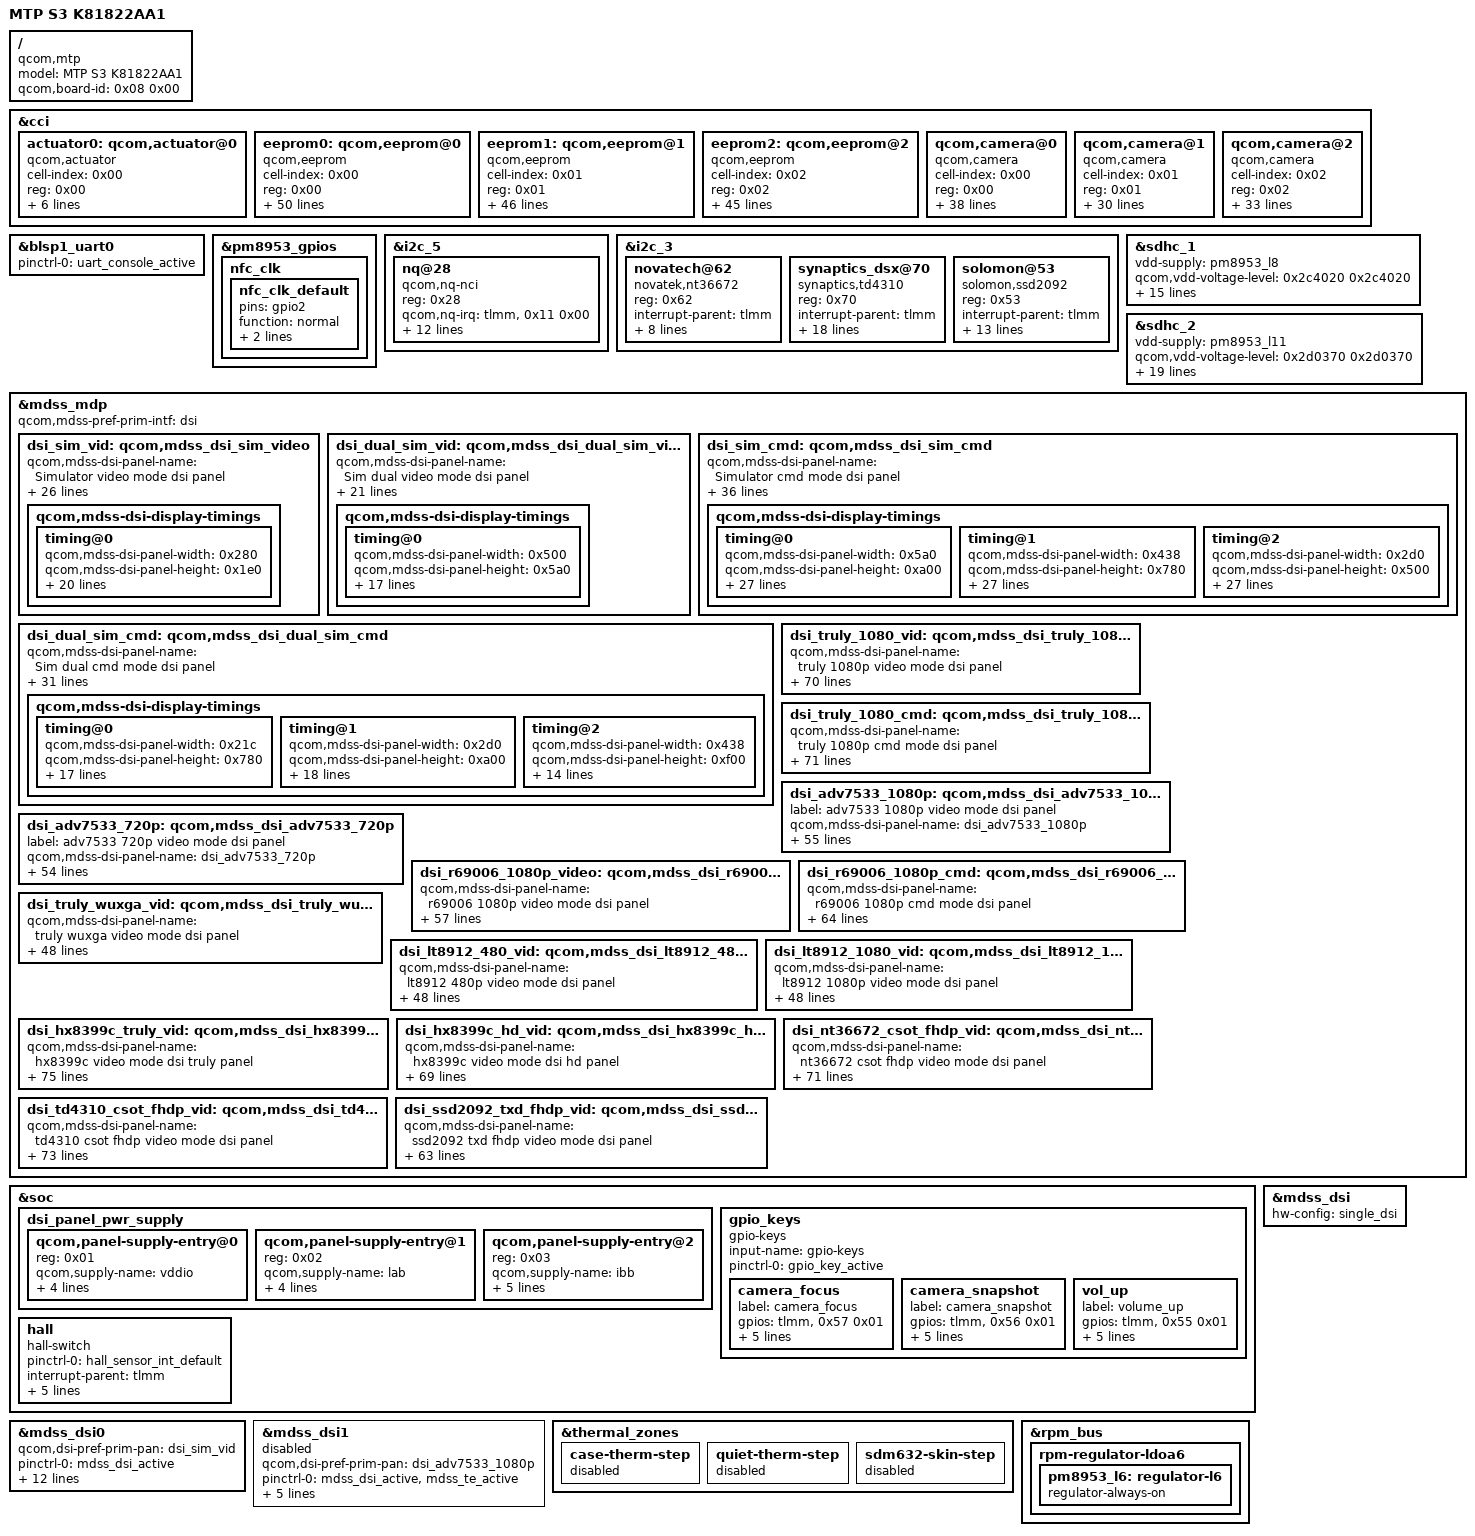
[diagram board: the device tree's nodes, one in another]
/dts-v1/;
/plugin/;

/ {
	model = "MTP S3 K81822AA1";
	compatible = "qcom,mtp";
	qcom,board-id = <0x08 0x00>;

	fragment@0 {
		target = <&cci>;

		__overlay__ {

			actuator0: qcom,actuator@0 {
				cell-index = <0x00>;
				reg = <0x00>;
				compatible = "qcom,actuator";
				qcom,cci-master = <0x00>;
				cam_vaf-supply = <&pm8953_l17>;
				qcom,cam-vreg-name = "cam_vaf";
				qcom,cam-vreg-min-voltage = <0x2b7cd0>;
				qcom,cam-vreg-max-voltage = <0x2b7cd0>;
				qcom,cam-vreg-op-mode = <0x13880>;
			};

			eeprom0: qcom,eeprom@0 {
				cell-index = <0x00>;
				reg = <0x00>;
				compatible = "qcom,eeprom";
				qcom,cci-master = <0x00>;
				qcom,eeprom-name = "gt24c64a_imx362";
				qcom,slave-addr = <0xa0>;
				qcom,num-blocks = <0x03>;
				qcom,page0 = <0x00 0x00 0x01 0x55 0x01 0x01>;
				qcom,pageen0 = <0x00 0x02 0x01 0xff 0x01 0x01>;
				qcom,poll0 = <0x00 0x00 0x02 0x00 0x01 0x01>;
				qcom,mem0 = <0x2b 0x00 0x02 0x00 0x01 0x00>;
				qcom,page1 = <0x00 0x00 0x01 0x55 0x01 0x01>;
				qcom,pageen1 = <0x00 0x02 0x01 0xff 0x01 0x01>;
				qcom,poll1 = <0x00 0x00 0x02 0x00 0x01 0x01>;
				qcom,mem1 = <0x132f 0x2b 0x02 0x00 0x01 0x00>;
				qcom,page2 = <0x00 0x00 0x01 0x55 0x01 0x01>;
				qcom,pageen2 = <0x00 0x02 0x01 0xff 0x01 0x01>;
				qcom,poll2 = <0x00 0x00 0x02 0x00 0x01 0x01>;
				qcom,mem2 = <0x2c 0x1a6c 0x02 0x00 0x01 0x00>;
				cam_vio-supply = <&pm8953_l6>;
				cam_vdig-supply = <&pm8953_l2>;
				cam_vana-supply = <&pm8953_l22>;
				qcom,cam-vreg-name = "cam_vio", "cam_vdig", "cam_vana";
				qcom,cam-vreg-min-voltage = <0x1b7740 0x100590 0x2ab980>;
				qcom,cam-vreg-max-voltage = <0x1b7740 0x100590 0x2ab980>;
				qcom,cam-vreg-op-mode = <0x13880 0x19a28 0x13880>;
				pinctrl-names = "cam_default", "cam_suspend";
				pinctrl-0 = <&cam_sensor_mclk0_default>, <&cam_sensor_rear_default>, <&cam_sensor_rear_vana>;
				pinctrl-1 = <&cam_sensor_mclk0_sleep>, <&cam_sensor_rear_sleep>, <&cam_sensor_rear_vana_sleep>;
				gpios = <&tlmm>, <0x1a 0x00>, <&tlmm>, <0x28 0x00>, <&tlmm>, <0x86 0x00>;
				qcom,gpio-reset = <0x01>;
				qcom,gpio-vana = <0x02>;
				qcom,gpio-req-tbl-num = <0x00 0x01 0x02>;
				qcom,gpio-req-tbl-flags = <0x01 0x00 0x00>;
				qcom,gpio-req-tbl-label = "CAMIF_MCLK0", "CAM_RESET0", "CAM_VANA";
				qcom,cam-power-seq-type = "sensor_gpio", "sensor_gpio", "sensor_vreg", "sensor_vreg";
				qcom,cam-power-seq-val = "sensor_gpio_vana", "sensor_gpio_vana", "cam_vdig", "cam_vio";
				qcom,cam-power-seq-cfg-val = <0x00 0x01 0x01 0x01>;
				qcom,cam-power-seq-delay = <0x01 0x01 0x01 0x01>;
				status = "ok";
				clocks = <&clock_gcc>, <0x266b3853>, <&clock_gcc>, <0x80902deb>;
				clock-names = "cam_src_clk", "cam_clk";
				qcom,clock-rates = <0x16e3600 0x00>;
			};

			eeprom1: qcom,eeprom@1 {
				cell-index = <0x01>;
				reg = <0x01>;
				compatible = "qcom,eeprom";
				qcom,cci-master = <0x00>;
				qcom,eeprom-name = "s5k5e9";
				qcom,slave-addr = <0xa0>;
				qcom,num-blocks = <0x02>;
				qcom,page0 = <0x00 0x00 0x01 0x55 0x01 0x01>;
				qcom,pageen0 = <0x00 0x02 0x01 0xff 0x01 0x01>;
				qcom,poll0 = <0x00 0x00 0x02 0x00 0x01 0x01>;
				qcom,mem0 = <0x2b 0x00 0x02 0x00 0x01 0x00>;
				qcom,page1 = <0x00 0x00 0x01 0x55 0x01 0x01>;
				qcom,pageen1 = <0x00 0x02 0x01 0xff 0x01 0x01>;
				qcom,poll1 = <0x00 0x00 0x02 0x00 0x01 0x01>;
				qcom,mem1 = <0x712 0x135a 0x02 0x00 0x01 0x00>;
				cam_vio-supply = <&pm8953_l6>;
				cam_vdig-supply = <&pm8953_l2>;
				cam_vana-supply = <&pm8953_l22>;
				qcom,cam-vreg-name = "cam_vio", "cam_vdig", "cam_vana";
				qcom,cam-vreg-min-voltage = <0x1b7740 0x100590 0x2ab980>;
				qcom,cam-vreg-max-voltage = <0x1b7740 0x100590 0x2ab980>;
				qcom,cam-vreg-op-mode = <0x13880 0x19a28 0x13880>;
				pinctrl-names = "cam_default", "cam_suspend";
				pinctrl-0 = <&cam_sensor_mclk0_default>, <&cam_sensor_rear_default>, <&cam_sensor_rear_vana>;
				pinctrl-1 = <&cam_sensor_mclk0_sleep>, <&cam_sensor_rear_sleep>, <&cam_sensor_rear_vana_sleep>;
				gpios = <&tlmm>, <0x1a 0x00>, <&tlmm>, <0x28 0x00>, <&tlmm>, <0x86 0x00>;
				qcom,gpio-reset = <0x01>;
				qcom,gpio-vana = <0x02>;
				qcom,gpio-req-tbl-num = <0x00 0x01 0x02>;
				qcom,gpio-req-tbl-flags = <0x01 0x00 0x00>;
				qcom,gpio-req-tbl-label = "CAMIF_MCLK0", "CAM_RESET0", "CAM_VANA";
				qcom,cam-power-seq-type = "sensor_gpio", "sensor_gpio", "sensor_vreg", "sensor_vreg";
				qcom,cam-power-seq-val = "sensor_gpio_vana", "sensor_gpio_vana", "cam_vdig", "cam_vio";
				qcom,cam-power-seq-cfg-val = <0x00 0x01 0x01 0x01>;
				qcom,cam-power-seq-delay = <0x01 0x01 0x01 0x01>;
				status = "ok";
				clocks = <&clock_gcc>, <0x266b3853>, <&clock_gcc>, <0x80902deb>;
				clock-names = "cam_src_clk", "cam_clk";
				qcom,clock-rates = <0x16e3600 0x00>;
			};

			eeprom2: qcom,eeprom@2 {
				cell-index = <0x02>;
				reg = <0x02>;
				qcom,eeprom-name = "s5k4h7";
				compatible = "qcom,eeprom";
				qcom,slave-addr = <0x5a>;
				qcom,cci-master = <0x01>;
				qcom,num-blocks = <0x01>;
				qcom,page0 = <0x00 0x100 0x02 0x01 0x01 0x01>;
				qcom,poll0 = <0x00 0x00 0x02 0x00 0x01 0x00>;
				qcom,mem0 = <0x7c0 0x00 0x02 0x00 0x01 0x00>;
				cam_vdig-supply = <&pm8953_l23>;
				cam_vio-supply = <&pm8953_l6>;
				cam_vana-supply = <&pm8953_l22>;
				qcom,cam-vreg-name = "cam_vdig", "cam_vio", "cam_vana";
				qcom,cam-vreg-min-voltage = <0x124f80 0x1b7740 0x2ab980>;
				qcom,cam-vreg-max-voltage = <0x124f80 0x1b7740 0x2ab980>;
				qcom,cam-vreg-op-mode = <0x19a28 0x13880 0x13880>;
				qcom,gpio-no-mux = <0x00>;
				pinctrl-names = "cam_default", "cam_suspend";
				pinctrl-0 = <&cam_sensor_mclk1_default>, <&cam_sensor_front1_default>;
				pinctrl-1 = <&cam_sensor_mclk1_sleep>, <&cam_sensor_front1_sleep>;
				gpios = <&tlmm>, <0x1b 0x00>, <&tlmm>, <0x81 0x00>, <&tlmm>, <0x82 0x00>;
				qcom,gpio-reset = <0x01>;
				qcom,gpio-standby = <0x02>;
				qcom,gpio-req-tbl-num = <0x00 0x01 0x02>;
				qcom,gpio-req-tbl-flags = <0x01 0x00 0x00>;
				qcom,gpio-req-tbl-label = "CAMIF_MCLK2", "CAM_RESET2", "CAM_STANDBY2";
				qcom,cam-power-seq-type = "sensor_gpio", "sensor_gpio", "sensor_vreg", "sensor_vreg", "sensor_vreg", "sensor_gpio", "sensor_gpio", "sensor_clk";
				qcom,cam-power-seq-val = "sensor_gpio_reset", "sensor_gpio_standby", "cam_vana", "cam_vio", "cam_vdig", "sensor_gpio_reset", "sensor_gpio_standby", "sensor_cam_mclk";
				qcom,cam-power-seq-cfg-val = <0x00 0x00 0x01 0x01 0x01 0x01 0x01 0x16e3600>;
				qcom,cam-power-seq-delay = <0x01 0x01 0x00 0x00 0x00 0x01 0x05 0x05>;
				status = "ok";
				clocks = <&clock_gcc>, <0xa73cad0c>, <&clock_gcc>, <0x5002d85f>;
				clock-names = "cam_src_clk", "cam_clk";
				qcom,clock-rates = <0x16e3600 0x00>;
			};

			qcom,camera@0 {
				cell-index = <0x00>;
				compatible = "qcom,camera";
				reg = <0x00>;
				qcom,csiphy-sd-index = <0x00>;
				qcom,csid-sd-index = <0x00>;
				qcom,mount-angle = <0x5a>;
				qcom,led-flash-src = <&led_flash0>;
				qcom,eeprom-src = <&eeprom0>;
				qcom,actuator-src = <&actuator0>;
				cam_vio-supply = <&pm8953_l6>;
				cam_vdig-supply = <&pm8953_l2>;
				cam_vaf-supply = <&pm8953_l17>;
				cam_vana-supply = <&pm8953_l22>;
				qcom,cam-vreg-name = "cam_vio", "cam_vdig", "cam_vaf", "cam_vana";
				qcom,cam-vreg-min-voltage = <0x1b7740 0x100590 0x2b7cd0 0x2ab980>;
				qcom,cam-vreg-max-voltage = <0x1b7740 0x100590 0x2b7cd0 0x2ab980>;
				qcom,cam-vreg-op-mode = <0x13880 0x19a28 0x186a0 0x13880>;
				pinctrl-names = "cam_default", "cam_suspend";
				pinctrl-0 = <&cam_sensor_mclk0_default>, <&cam_sensor_rear_default>, <&cam_sensor_rear_vana>;
				pinctrl-1 = <&cam_sensor_mclk0_sleep>, <&cam_sensor_rear_sleep>, <&cam_sensor_rear_vana_sleep>;
				gpios = <&tlmm>, <0x1a 0x00>, <&tlmm>, <0x28 0x00>, <&tlmm>, <0x86 0x00>;
				qcom,gpio-reset = <0x01>;
				qcom,gpio-vana = <0x02>;
				qcom,gpio-req-tbl-num = <0x00 0x01 0x02>;
				qcom,gpio-req-tbl-flags = <0x01 0x00 0x00>;
				qcom,gpio-req-tbl-label = "CAMIF_MCLK0", "CAM_RESET0", "CAM_VANA";
				qcom,sensor-position = <0x00>;
				qcom,sensor-mode = <0x00>;
				qcom,cci-master = <0x00>;
				status = "ok";
				clocks = <&clock_gcc>, <0x266b3853>, <&clock_gcc>, <0x80902deb>;
				clock-names = "cam_src_clk", "cam_clk";
				qcom,clock-rates = <0x16e3600 0x00>;
			};

			qcom,camera@1 {
				cell-index = <0x01>;
				compatible = "qcom,camera";
				reg = <0x01>;
				qcom,csiphy-sd-index = <0x01>;
				qcom,csid-sd-index = <0x01>;
				qcom,mount-angle = <0x5a>;
				qcom,eeprom-src = <&eeprom1>;
				cam_vdig-supply = <&pm8953_l23>;
				cam_vana-supply = <&pm8953_l22>;
				cam_vio-supply = <&pm8953_l6>;
				qcom,cam-vreg-name = "cam_vdig", "cam_vio", "cam_vana";
				qcom,cam-vreg-min-voltage = <0x124f80 0x1b7740 0x2ab980>;
				qcom,cam-vreg-max-voltage = <0x124f80 0x1b7740 0x2ab980>;
				qcom,cam-vreg-op-mode = <0x30d40 0x13880 0x13880>;
				pinctrl-names = "cam_default", "cam_suspend";
				pinctrl-0 = <&cam_sensor_mclk2_default>, <&cam_sensor_front_default>;
				pinctrl-1 = <&cam_sensor_mclk2_sleep>, <&cam_sensor_front_sleep>;
				gpios = <&tlmm>, <0x1c 0x00>, <&tlmm>, <0x83 0x00>;
				qcom,gpio-reset = <0x01>;
				qcom,gpio-req-tbl-num = <0x00 0x01>;
				qcom,gpio-req-tbl-flags = <0x01 0x00>;
				qcom,gpio-req-tbl-label = "CAMIF_MCLK1", "CAM_RESET1";
				qcom,sensor-position = <0x100>;
				qcom,sensor-mode = <0x01>;
				qcom,cci-master = <0x01>;
				status = "ok";
				clocks = <&clock_gcc>, <0x42545468>, <&clock_gcc>, <0x222f8fff>;
				clock-names = "cam_src_clk", "cam_clk";
				qcom,clock-rates = <0x16e3600 0x00>;
			};

			qcom,camera@2 {
				cell-index = <0x02>;
				compatible = "qcom,camera";
				reg = <0x02>;
				qcom,csiphy-sd-index = <0x02>;
				qcom,csid-sd-index = <0x02>;
				qcom,mount-angle = <0x10e>;
				qcom,eeprom-src = <&eeprom2>;
				cam_vdig-supply = <&pm8953_l23>;
				cam_vio-supply = <&pm8953_l6>;
				cam_vana-supply = <&pm8953_l22>;
				qcom,cam-vreg-name = "cam_vdig", "cam_vio", "cam_vana";
				qcom,cam-vreg-min-voltage = <0x124f80 0x1b7740 0x2ab980>;
				qcom,cam-vreg-max-voltage = <0x124f80 0x1b7740 0x2ab980>;
				qcom,cam-vreg-op-mode = <0x19a28 0x13880 0x13880>;
				qcom,gpio-no-mux = <0x00>;
				pinctrl-names = "cam_default", "cam_suspend";
				pinctrl-0 = <&cam_sensor_mclk1_default>, <&cam_sensor_front1_default>;
				pinctrl-1 = <&cam_sensor_mclk1_sleep>, <&cam_sensor_front1_sleep>;
				gpios = <&tlmm>, <0x1b 0x00>, <&tlmm>, <0x81 0x00>, <&tlmm>, <0x82 0x00>;
				qcom,gpio-reset = <0x01>;
				qcom,gpio-standby = <0x02>;
				qcom,gpio-req-tbl-num = <0x00 0x01 0x02>;
				qcom,gpio-req-tbl-flags = <0x01 0x00 0x00>;
				qcom,gpio-req-tbl-label = "CAMIF_MCLK2", "CAM_RESET2", "CAM_STANDBY2";
				qcom,sensor-position = <0x01>;
				qcom,sensor-mode = <0x00>;
				qcom,cci-master = <0x01>;
				status = "ok";
				clocks = <&clock_gcc>, <0xa73cad0c>, <&clock_gcc>, <0x5002d85f>;
				clock-names = "cam_src_clk", "cam_clk";
				qcom,clock-rates = <0x16e3600 0x00>;
			};
		};
	};

	fragment@1 {
		target = <&blsp1_uart0>;

		__overlay__ {
			status = "ok";
			pinctrl-names = "default";
			pinctrl-0 = <&uart_console_active>;
		};
	};

	fragment@2 {
		target = <&pm8953_gpios>;

		__overlay__ {

			nfc_clk {

				nfc_clk_default: nfc_clk_default {
					pins = "gpio2";
					function = "normal";
					input-enable;
					power-source = <0x01>;
				};
			};
		};
	};

	fragment@3 {
		target = <&i2c_5>;

		__overlay__ {
			status = "ok";

			nq@28 {
				compatible = "qcom,nq-nci";
				reg = <0x28>;
				qcom,nq-irq = <&tlmm>, <0x11 0x00>;
				qcom,nq-ven = <&tlmm>, <0x10 0x00>;
				qcom,nq-firm = <&tlmm>, <0x3e 0x00>;
				qcom,nq-clkreq = <&pm8953_gpios>, <0x02 0x00>;
				qcom,nq-esepwr = <&tlmm>, <0x8d 0x00>;
				interrupt-parent = <&tlmm>;
				qcom,clk-src = "BBCLK2";
				interrupts = <0x11 0x00>;
				interrupt-names = "nfc_irq";
				pinctrl-names = "nfc_active", "nfc_suspend";
				pinctrl-0 = <&nfc_int_active>, <&nfc_disable_active>, <&nfc_clk_default>;
				pinctrl-1 = <&nfc_int_suspend>, <&nfc_disable_suspend>;
				clocks = <&clock_gcc>, <0x498938e5>;
				clock-names = "ref_clk";
			};
		};
	};

	fragment@4 {
		target = <&i2c_3>;

		__overlay__ {
			status = "okay";

			novatech@62 {
				compatible = "novatek,nt36672", "novatek,NVT-ts";
				reg = <0x62>;
				interrupt-parent = <&tlmm>;
				status = "ok";
				novatek,reset-gpio = <&tlmm>, <0x40 0x00>;
				novatek,irq-gpio = <&tlmm>, <0x41 0x2001>;
				vdd-supply = <&pm8953_l5>;
				lab-supply = <&lcdb_ldo_vreg>;
				ibb-supply = <&lcdb_ncp_vreg>;
				touchpanel,rst-gpio = <&tlmm>, <0x40 0x00>;
				touchpanel,irq-gpio = <&tlmm>, <0x41 0x00>;
				touchpanel,open_short_not_use_fw;
			};

			synaptics_dsx@70 {
				compatible = "synaptics,td4310", "synaptics,dsx-i2c";
				reg = <0x70>;
				interrupt-parent = <&tlmm>;
				interrupts = <0x41 0x2008>;
				pinctrl-names = "default";
				pinctrl-0 = <&ts_int_active>;
				vdd-supply = <&pm8953_l5>;
				lab-supply = <&lcdb_ldo_vreg>;
				ibb-supply = <&lcdb_ncp_vreg>;
				synaptics,bus-reg-name = "vdd";
				synaptics,lab-reg-name = "lab";
				synaptics,ibb-reg-name = "ibb";
				synaptics,ub-i2c-addr = <0x2c>;
				synaptics,irq-gpio = <&tlmm>, <0x41 0x2008>;
				synaptics,rst-gpio = <&tlmm>, <0x3d 0x00>;
				synaptics,irq-on-state = <0x00>;
				synaptics,power-delay-ms = <0x00>;
				synaptics,reset-delay-ms = <0xc8>;
				synaptics,reset-on-state = <0x00>;
				synaptics,reset-active-ms = <0x14>;
				touchpanel,rst-gpio = <&tlmm>, <0x3d 0x00>;
				touchpanel,irq-gpio = <&tlmm>, <0x41 0x00>;
			};

			solomon@53 {
				compatible = "solomon,ssd2092";
				reg = <0x53>;
				interrupt-parent = <&tlmm>;
				interrupts = <0x41 0x2008>;
				vcc-i2c-supply = <&pm8953_l5>;
				lab-supply = <&lcdb_ldo_vreg>;
				ibb-supply = <&lcdb_ncp_vreg>;
				solomon,bus-reg-name = "vcc-i2c";
				solomon,lab-reg-name = "lab";
				solomon,ibb-reg-name = "ibb";
				interrupt-gpios = <&tlmm>, <0x41 0x00>;
				reset-gpios = <&tlmm>, <0x40 0x00>;
				lcd-reset-gpios = <&tlmm>, <0x3d 0x00>;
				touchpanel,rst-gpio = <&tlmm>, <0x3d 0x00>;
				touchpanel,irq-gpio = <&tlmm>, <0x41 0x00>;
				touchpanel,open_short_not_use_fw;
			};
		};
	};

	fragment@5 {
		target = <&sdhc_1>;

		__overlay__ {
			vdd-supply = <&pm8953_l8>;
			qcom,vdd-voltage-level = <0x2c4020 0x2c4020>;
			qcom,vdd-current-level = <0xc8 0x8b290>;
			vdd-io-supply = <&pm8953_l5>;
			qcom,vdd-io-always-on;
			qcom,vdd-io-lpm-sup;
			qcom,vdd-io-voltage-level = <0x1b7740 0x1b7740>;
			qcom,vdd-io-current-level = <0xc8 0x4f588>;
			pinctrl-names = "active", "sleep";
			pinctrl-0 = <&sdc1_clk_on>, <&sdc1_cmd_on>, <&sdc1_data_on>, <&sdc1_rclk_on>;
			pinctrl-1 = <&sdc1_clk_off>, <&sdc1_cmd_off>, <&sdc1_data_off>, <&sdc1_rclk_off>;
			qcom,clk-rates = <0x61a80 0x1312d00 0x17d7840 0x2faf080 0x5f5e100 0xb71b000 0x16e36000>;
			qcom,nonremovable;
			qcom,bus-speed-mode = "HS400_1p8v", "HS200_1p8v", "DDR_1p8v";
			status = "ok";
		};
	};

	fragment@6 {
		target = <&sdhc_2>;

		__overlay__ {
			vdd-supply = <&pm8953_l11>;
			qcom,vdd-voltage-level = <0x2d0370 0x2d0370>;
			qcom,vdd-current-level = <0x3a98 0xc3500>;
			vdd-io-supply = <&pm8953_l12>;
			qcom,vdd-io-voltage-level = <0x1b7740 0x2d0370>;
			qcom,vdd-io-current-level = <0xc8 0x55f0>;
			pinctrl-names = "active", "sleep";
			pinctrl-0 = <&sdc2_clk_on>, <&sdc2_cmd_on>, <&sdc2_data_on>, <&sdc2_cd_on>;
			pinctrl-1 = <&sdc2_clk_off>, <&sdc2_cmd_off>, <&sdc2_data_off>;
			#address-cells = <0x00>;
			interrupt-parent = <&sdhc_2>;
			interrupts = <0x00 0x01 0x02>;
			#interrupt-cells = <0x01>;
			interrupt-map-mask = <0xffffffff>;
			interrupt-map = <0x00>, <&intc>, <0x00 0x7d 0x00 0x01>, <&intc>, <0x00 0xdd 0x00 0x02>, <&tlmm>, <0x85 0x00>;
			interrupt-names = "hc_irq", "pwr_irq", "status_irq";
			cd-gpios = <&tlmm>, <0x85 0x00>;
			qcom,clk-rates = <0x61a80 0x1312d00 0x17d7840 0x2faf080 0x5f5e100 0xbebc200>;
			qcom,bus-speed-mode = "SDR12", "SDR25", "SDR50", "DDR50", "SDR104";
			status = "ok";
		};
	};

	fragment@7 {
		target = <&mdss_mdp>;

		__overlay__ {

			dsi_sim_vid: qcom,mdss_dsi_sim_video {
				qcom,mdss-dsi-panel-name = "Simulator video mode dsi panel";
				qcom,mdss-dsi-panel-type = "dsi_video_mode";
				qcom,mdss-dsi-virtual-channel-id = <0x00>;
				qcom,mdss-dsi-stream = <0x00>;
				qcom,mdss-dsi-bpp = <0x18>;
				qcom,mdss-dsi-underflow-color = <0xff>;
				qcom,mdss-dsi-border-color = <0x00>;
				qcom,mdss-dsi-panel-hdr-enabled;
				qcom,mdss-dsi-panel-hdr-color-primaries = <0x38a4 0x3c8c 0x7d00 0x4268 0x3c8c 0x7530 0x1f40 0xbb8>;
				qcom,mdss-dsi-panel-peak-brightness = <0x401640>;
				qcom,mdss-dsi-panel-blackness-level = <0xc9e>;
				qcom,mdss-dsi-traffic-mode = "non_burst_sync_event";
				qcom,mdss-dsi-bllp-eof-power-mode;
				qcom,mdss-dsi-bllp-power-mode;
				qcom,mdss-dsi-lane-0-state;
				qcom,mdss-dsi-lane-1-state;
				qcom,mdss-dsi-lane-2-state;
				qcom,mdss-dsi-lane-3-state;
				qcom,mdss-dsi-t-clk-post = <0x04>;
				qcom,mdss-dsi-t-clk-pre = <0x1b>;
				qcom,mdss-dsi-dma-trigger = "trigger_sw";
				qcom,mdss-dsi-mdp-trigger = "none";
				qcom,mdss-dsi-reset-sequence = <0x01 0x00 0x00 0x00 0x01 0x00>;
				qcom,panel-ack-disabled;

				qcom,mdss-dsi-display-timings {

					timing@0 {
						qcom,mdss-dsi-panel-width = <0x280>;
						qcom,mdss-dsi-panel-height = <0x1e0>;
						qcom,mdss-dsi-h-front-porch = <0x08>;
						qcom,mdss-dsi-h-back-porch = <0x08>;
						qcom,mdss-dsi-h-pulse-width = <0x08>;
						qcom,mdss-dsi-h-sync-skew = <0x00>;
						qcom,mdss-dsi-v-back-porch = <0x06>;
						qcom,mdss-dsi-v-front-porch = <0x06>;
						qcom,mdss-dsi-v-pulse-width = <0x02>;
						qcom,mdss-dsi-h-left-border = <0x00>;
						qcom,mdss-dsi-h-right-border = <0x00>;
						qcom,mdss-dsi-v-top-border = <0x00>;
						qcom,mdss-dsi-v-bottom-border = <0x00>;
						qcom,mdss-dsi-panel-framerate = <0x3c>;
						qcom,mdss-dsi-panel-timings = <0x00 0x00 0x00>;
						qcom,mdss-dsi-on-command = [32 01 00 00 00 00 02 00 00];
						qcom,mdss-dsi-off-command = [22 01 00 00 00 00 02 00 00];
						qcom,mdss-dsi-on-command-state = "dsi_lp_mode";
						qcom,mdss-dsi-off-command-state = "dsi_lp_mode";
						qcom,mdss-dsi-h-sync-pulse = <0x00>;
					};
				};
			};
		};
	};

	fragment@8 {
		target = <&mdss_mdp>;

		__overlay__ {

			dsi_dual_sim_vid: qcom,mdss_dsi_dual_sim_video {
				qcom,mdss-dsi-panel-name = "Sim dual video mode dsi panel";
				qcom,mdss-dsi-panel-type = "dsi_video_mode";
				qcom,mdss-dsi-virtual-channel-id = <0x00>;
				qcom,mdss-dsi-stream = <0x00>;
				qcom,mdss-dsi-bpp = <0x18>;
				qcom,mdss-dsi-underflow-color = <0xff>;
				qcom,mdss-dsi-border-color = <0x00>;
				qcom,mdss-dsi-traffic-mode = "non_burst_sync_event";
				qcom,mdss-dsi-bllp-eof-power-mode;
				qcom,mdss-dsi-bllp-power-mode;
				qcom,mdss-dsi-panel-broadcast-mode;
				qcom,mdss-dsi-lane-0-state;
				qcom,mdss-dsi-lane-1-state;
				qcom,mdss-dsi-lane-2-state;
				qcom,mdss-dsi-lane-3-state;
				qcom,mdss-dsi-bl-max-level = <0xfff>;
				qcom,mdss-dsi-dma-trigger = "trigger_sw";
				qcom,mdss-dsi-mdp-trigger = "none";
				qcom,mdss-dsi-reset-sequence = <0x01 0x14 0x00 0xc8 0x01 0x14>;
				qcom,panel-ack-disabled;

				qcom,mdss-dsi-display-timings {

					timing@0 {
						qcom,mdss-dsi-panel-width = <0x500>;
						qcom,mdss-dsi-panel-height = <0x5a0>;
						qcom,mdss-dsi-h-front-porch = <0x78>;
						qcom,mdss-dsi-h-back-porch = <0x2c>;
						qcom,mdss-dsi-h-pulse-width = <0x10>;
						qcom,mdss-dsi-h-sync-skew = <0x00>;
						qcom,mdss-dsi-v-back-porch = <0x04>;
						qcom,mdss-dsi-v-front-porch = <0x08>;
						qcom,mdss-dsi-v-pulse-width = <0x04>;
						qcom,mdss-dsi-h-left-border = <0x00>;
						qcom,mdss-dsi-h-right-border = <0x00>;
						qcom,mdss-dsi-v-top-border = <0x00>;
						qcom,mdss-dsi-v-bottom-border = <0x00>;
						qcom,mdss-dsi-h-sync-pulse = <0x00>;
						qcom,mdss-dsi-panel-framerate = <0x3c>;
						qcom,mdss-dsi-on-command-state = "dsi_lp_mode";
						qcom,mdss-dsi-off-command = [05 01 00 00 32 00 02 28 00 05 01 00 00 78 00 02 10 00];
						qcom,mdss-dsi-off-command-state = "dsi_hs_mode";
					};
				};
			};
		};
	};

	fragment@9 {
		target = <&mdss_mdp>;

		__overlay__ {

			dsi_sim_cmd: qcom,mdss_dsi_sim_cmd {
				qcom,mdss-dsi-panel-name = "Simulator cmd mode dsi panel";
				qcom,mdss-dsi-panel-type = "dsi_cmd_mode";
				qcom,mdss-dsi-virtual-channel-id = <0x00>;
				qcom,mdss-dsi-stream = <0x00>;
				qcom,mdss-dsi-bpp = <0x18>;
				qcom,mdss-dsi-color-order = "rgb_swap_rgb";
				qcom,mdss-dsi-underflow-color = <0xff>;
				qcom,mdss-dsi-border-color = <0x00>;
				qcom,mdss-dsi-traffic-mode = "non_burst_sync_event";
				qcom,mdss-dsi-bllp-eof-power-mode;
				qcom,mdss-dsi-bllp-power-mode;
				qcom,mdss-dsi-lane-0-state;
				qcom,mdss-dsi-lane-1-state;
				qcom,mdss-dsi-lane-2-state;
				qcom,mdss-dsi-lane-3-state;
				qcom,mdss-dsi-reset-sequence = <0x01 0x0a 0x00 0x0a 0x01 0x0a>;
				qcom,mdss-dsi-t-clk-post = <0x03>;
				qcom,mdss-dsi-t-clk-pre = <0x27>;
				qcom,mdss-dsi-bl-max-level = <0xfff>;
				qcom,mdss-dsi-dma-trigger = "trigger_sw";
				qcom,mdss-dsi-mdp-trigger = "none";
				qcom,mdss-dsi-te-pin-select = <0x01>;
				qcom,mdss-dsi-wr-mem-start = <0x2c>;
				qcom,mdss-dsi-wr-mem-continue = <0x3c>;
				qcom,mdss-dsi-te-dcs-command = <0x01>;
				qcom,mdss-dsi-te-check-enable;
				qcom,mdss-dsi-te-using-wd;
				qcom,mdss-dsi-te-using-te-pin;
				qcom,mdss-dsi-panel-hdr-enabled;
				qcom,ulps-enabled;
				qcom,mdss-dsi-panel-hdr-color-primaries = <0x38a4 0x3c8c 0x7d00 0x4268 0x3c8c 0x7530 0x1f40 0xbb8>;
				qcom,mdss-dsi-panel-peak-brightness = <0x401640>;
				qcom,mdss-dsi-panel-blackness-level = <0xc9e>;
				qcom,panel-ack-disabled;

				qcom,mdss-dsi-display-timings {

					timing@0 {
						qcom,mdss-dsi-panel-width = <0x5a0>;
						qcom,mdss-dsi-panel-height = <0xa00>;
						qcom,mdss-dsi-h-front-porch = <0x78>;
						qcom,mdss-dsi-h-back-porch = <0x64>;
						qcom,mdss-dsi-h-pulse-width = <0x28>;
						qcom,mdss-dsi-h-sync-skew = <0x00>;
						qcom,mdss-dsi-v-back-porch = <0x64>;
						qcom,mdss-dsi-v-front-porch = <0x64>;
						qcom,mdss-dsi-v-pulse-width = <0x28>;
						qcom,mdss-dsi-h-left-border = <0x00>;
						qcom,mdss-dsi-h-right-border = <0x00>;
						qcom,mdss-dsi-v-top-border = <0x00>;
						qcom,mdss-dsi-v-bottom-border = <0x00>;
						qcom,mdss-dsi-panel-framerate = <0x3c>;
						qcom,mdss-dsi-panel-timings = <0x210909 0x24230808 0x8030400>;
						qcom,mdss-dsi-on-command = <0x29010000 0x2b0 0x3050100 0xa0001 0x150100 0xa0002 0x3a773901 0xa00 0x52a0000 0x4ff3901 0xa00 0x52b0000 0x59f1501 0xa00 0x2350039 0x100000a 0x34400 0x150100 0xa0002 0x51ff1501 0xa00 0x2532415 0x100000a 0x25500 0x5010000 0x78000111 0x5010000 0x10000129>;
						qcom,mdss-dsi-on-command-state = "dsi_lp_mode";
						qcom,mdss-dsi-off-command = [05 01 00 00 32 00 02 28 00 05 01 00 00 78 00 02 10 00];
						qcom,mdss-dsi-off-command-state = "dsi_hs_mode";
						qcom,compression-mode = "dsc";
						qcom,mdss-dsc-slice-height = <0x28>;
						qcom,mdss-dsc-slice-width = <0x2d0>;
						qcom,mdss-dsc-slice-per-pkt = <0x01>;
						qcom,mdss-dsc-bit-per-component = <0x08>;
						qcom,mdss-dsc-bit-per-pixel = <0x08>;
						qcom,mdss-dsc-block-prediction-enable;
					};

					timing@1 {
						qcom,mdss-dsi-panel-width = <0x438>;
						qcom,mdss-dsi-panel-height = <0x780>;
						qcom,mdss-dsi-h-front-porch = <0x78>;
						qcom,mdss-dsi-h-back-porch = <0x1cc>;
						qcom,mdss-dsi-h-pulse-width = <0x28>;
						qcom,mdss-dsi-h-sync-skew = <0x00>;
						qcom,mdss-dsi-v-back-porch = <0x64>;
						qcom,mdss-dsi-v-front-porch = <0x2e4>;
						qcom,mdss-dsi-v-pulse-width = <0x28>;
						qcom,mdss-dsi-h-left-border = <0x00>;
						qcom,mdss-dsi-h-right-border = <0x00>;
						qcom,mdss-dsi-v-top-border = <0x00>;
						qcom,mdss-dsi-v-bottom-border = <0x00>;
						qcom,mdss-dsi-panel-framerate = <0x3c>;
						qcom,mdss-dsi-panel-timings = <0x210909 0x24230808 0x8030400>;
						qcom,mdss-dsi-on-command = <0x29010000 0x2b0 0x3050100 0xa0001 0x150100 0xa0002 0x3a773901 0xa00 0x52a0000 0x4ff3901 0xa00 0x52b0000 0x59f1501 0xa00 0x2350039 0x100000a 0x34400 0x150100 0xa0002 0x51ff1501 0xa00 0x2532415 0x100000a 0x25500 0x5010000 0x78000111 0x5010000 0x10000129>;
						qcom,mdss-dsi-on-command-state = "dsi_lp_mode";
						qcom,mdss-dsi-off-command = [05 01 00 00 32 00 02 28 00 05 01 00 00 78 00 02 10 00];
						qcom,mdss-dsi-off-command-state = "dsi_hs_mode";
						qcom,compression-mode = "dsc";
						qcom,mdss-dsc-slice-height = <0x28>;
						qcom,mdss-dsc-slice-width = <0x21c>;
						qcom,mdss-dsc-slice-per-pkt = <0x01>;
						qcom,mdss-dsc-bit-per-component = <0x08>;
						qcom,mdss-dsc-bit-per-pixel = <0x08>;
						qcom,mdss-dsc-block-prediction-enable;
					};

					timing@2 {
						qcom,mdss-dsi-panel-width = <0x2d0>;
						qcom,mdss-dsi-panel-height = <0x500>;
						qcom,mdss-dsi-h-front-porch = <0x64>;
						qcom,mdss-dsi-h-back-porch = <0x348>;
						qcom,mdss-dsi-h-pulse-width = <0x28>;
						qcom,mdss-dsi-h-sync-skew = <0x00>;
						qcom,mdss-dsi-v-back-porch = <0x64>;
						qcom,mdss-dsi-v-front-porch = <0x564>;
						qcom,mdss-dsi-v-pulse-width = <0x28>;
						qcom,mdss-dsi-h-left-border = <0x00>;
						qcom,mdss-dsi-h-right-border = <0x00>;
						qcom,mdss-dsi-v-top-border = <0x00>;
						qcom,mdss-dsi-v-bottom-border = <0x00>;
						qcom,mdss-dsi-panel-framerate = <0x3c>;
						qcom,mdss-dsi-panel-timings = <0x210909 0x24230808 0x8030400>;
						qcom,mdss-dsi-on-command = <0x29010000 0x2b0 0x3050100 0xa0001 0x150100 0xa0002 0x3a773901 0xa00 0x52a0000 0x4ff3901 0xa00 0x52b0000 0x59f1501 0xa00 0x2350039 0x100000a 0x34400 0x150100 0xa0002 0x51ff1501 0xa00 0x2532415 0x100000a 0x25500 0x5010000 0x78000111 0x5010000 0x10000129>;
						qcom,mdss-dsi-on-command-state = "dsi_lp_mode";
						qcom,mdss-dsi-off-command = [05 01 00 00 32 00 02 28 00 05 01 00 00 78 00 02 10 00];
						qcom,mdss-dsi-off-command-state = "dsi_hs_mode";
						qcom,compression-mode = "dsc";
						qcom,mdss-dsc-slice-height = <0x28>;
						qcom,mdss-dsc-slice-width = <0x168>;
						qcom,mdss-dsc-slice-per-pkt = <0x01>;
						qcom,mdss-dsc-bit-per-component = <0x08>;
						qcom,mdss-dsc-bit-per-pixel = <0x08>;
						qcom,mdss-dsc-block-prediction-enable;
					};
				};
			};
		};
	};

	fragment@10 {
		target = <&mdss_mdp>;

		__overlay__ {

			dsi_dual_sim_cmd: qcom,mdss_dsi_dual_sim_cmd {
				qcom,mdss-dsi-panel-name = "Sim dual cmd mode dsi panel";
				qcom,mdss-dsi-panel-type = "dsi_cmd_mode";
				qcom,mdss-dsi-virtual-channel-id = <0x00>;
				qcom,mdss-dsi-stream = <0x00>;
				qcom,mdss-dsi-bpp = <0x18>;
				qcom,mdss-dsi-color-order = "rgb_swap_rgb";
				qcom,mdss-dsi-underflow-color = <0xff>;
				qcom,mdss-dsi-border-color = <0x00>;
				qcom,mdss-dsi-traffic-mode = "non_burst_sync_event";
				qcom,mdss-dsi-bllp-eof-power-mode;
				qcom,mdss-dsi-bllp-power-mode;
				qcom,cmd-sync-wait-broadcast;
				qcom,mdss-dsi-lane-0-state;
				qcom,mdss-dsi-lane-1-state;
				qcom,mdss-dsi-lane-2-state;
				qcom,mdss-dsi-lane-3-state;
				qcom,mdss-dsi-hor-line-idle = <0x00 0x28 0x100 0x28 0x78 0x80 0x78 0xf0 0x40>;
				qcom,mdss-dsi-reset-sequence = <0x01 0x0a 0x00 0x0a 0x01 0x0a>;
				qcom,mdss-dsi-bl-max-level = <0xfff>;
				qcom,mdss-dsi-dma-trigger = "trigger_sw";
				qcom,mdss-dsi-mdp-trigger = "none";
				qcom,mdss-dsi-te-pin-select = <0x01>;
				qcom,mdss-dsi-wr-mem-start = <0x2c>;
				qcom,mdss-dsi-wr-mem-continue = <0x3c>;
				qcom,mdss-dsi-te-dcs-command = <0x01>;
				qcom,mdss-dsi-te-check-enable;
				qcom,mdss-dsi-te-using-wd;
				qcom,mdss-dsi-te-using-te-pin;
				qcom,panel-ack-disabled;

				qcom,mdss-dsi-display-timings {

					timing@0 {
						qcom,mdss-dsi-panel-width = <0x21c>;
						qcom,mdss-dsi-panel-height = <0x780>;
						qcom,mdss-dsi-h-front-porch = <0x1c>;
						qcom,mdss-dsi-h-back-porch = <0x04>;
						qcom,mdss-dsi-h-pulse-width = <0x04>;
						qcom,mdss-dsi-h-sync-skew = <0x00>;
						qcom,mdss-dsi-v-back-porch = <0x0c>;
						qcom,mdss-dsi-v-front-porch = <0x0c>;
						qcom,mdss-dsi-v-pulse-width = <0x02>;
						qcom,mdss-dsi-h-left-border = <0x00>;
						qcom,mdss-dsi-h-right-border = <0x00>;
						qcom,mdss-dsi-v-top-border = <0x00>;
						qcom,mdss-dsi-v-bottom-border = <0x00>;
						qcom,mdss-dsi-panel-framerate = <0x78>;
						qcom,mdss-dsi-on-command = <0x5010000 0x129>;
						qcom,mdss-dsi-on-command-state = "dsi_lp_mode";
						qcom,mdss-dsi-off-command = [05 01 00 00 00 00 02 28 00 05 01 00 00 00 00 02 10 00];
						qcom,mdss-dsi-off-command-state = "dsi_hs_mode";
					};

					timing@1 {
						qcom,mdss-dsi-panel-width = <0x2d0>;
						qcom,mdss-dsi-panel-height = <0xa00>;
						qcom,mdss-dsi-h-front-porch = <0x64>;
						qcom,mdss-dsi-h-back-porch = <0x20>;
						qcom,mdss-dsi-h-pulse-width = <0x10>;
						qcom,mdss-dsi-h-sync-skew = <0x00>;
						qcom,mdss-dsi-v-back-porch = <0x07>;
						qcom,mdss-dsi-v-front-porch = <0x08>;
						qcom,mdss-dsi-v-pulse-width = <0x01>;
						qcom,mdss-dsi-h-sync-pulse = <0x00>;
						qcom,mdss-dsi-h-left-border = <0x00>;
						qcom,mdss-dsi-h-right-border = <0x00>;
						qcom,mdss-dsi-v-top-border = <0x00>;
						qcom,mdss-dsi-v-bottom-border = <0x00>;
						qcom,mdss-dsi-panel-framerate = <0x3c>;
						qcom,mdss-dsi-on-command = <0x5010000 0x129>;
						qcom,mdss-dsi-on-command-state = "dsi_lp_mode";
						qcom,mdss-dsi-off-command = [05 01 00 00 00 00 02 28 00 05 01 00 00 00 00 02 10 00];
						qcom,mdss-dsi-off-command-state = "dsi_hs_mode";
					};

					timing@2 {
						qcom,mdss-dsi-panel-width = <0x438>;
						qcom,mdss-dsi-panel-height = <0xf00>;
						qcom,mdss-dsi-h-front-porch = <0x1e>;
						qcom,mdss-dsi-h-back-porch = <0x64>;
						qcom,mdss-dsi-h-pulse-width = <0x04>;
						qcom,mdss-dsi-h-sync-skew = <0x00>;
						qcom,mdss-dsi-v-back-porch = <0x07>;
						qcom,mdss-dsi-v-front-porch = <0x08>;
						qcom,mdss-dsi-v-pulse-width = <0x01>;
						qcom,mdss-dsi-h-sync-pulse = <0x00>;
						qcom,mdss-dsi-panel-framerate = <0x28>;
						qcom,mdss-dsi-on-command = <0x5010000 0x129>;
						qcom,mdss-dsi-on-command-state = "dsi_lp_mode";
						qcom,mdss-dsi-off-command = [05 01 00 00 00 00 02 28 00 05 01 00 00 00 00 02 10 00];
						qcom,mdss-dsi-off-command-state = "dsi_hs_mode";
					};
				};
			};
		};
	};

	fragment@11 {
		target = <&mdss_mdp>;

		__overlay__ {

			dsi_truly_1080_vid: qcom,mdss_dsi_truly_1080p_video {
				qcom,mdss-dsi-panel-name = "truly 1080p video mode dsi panel";
				qcom,mdss-dsi-panel-type = "dsi_video_mode";
				qcom,mdss-dsi-panel-framerate = <0x3c>;
				qcom,mdss-dsi-virtual-channel-id = <0x00>;
				qcom,mdss-dsi-stream = <0x00>;
				qcom,mdss-dsi-panel-width = <0x438>;
				qcom,mdss-dsi-panel-height = <0x780>;
				qcom,mdss-dsi-h-front-porch = <0x60>;
				qcom,mdss-dsi-h-back-porch = <0x40>;
				qcom,mdss-dsi-h-pulse-width = <0x10>;
				qcom,mdss-dsi-h-sync-skew = <0x00>;
				qcom,mdss-dsi-v-back-porch = <0x10>;
				qcom,mdss-dsi-v-front-porch = <0x04>;
				qcom,mdss-dsi-v-pulse-width = <0x01>;
				qcom,mdss-dsi-h-left-border = <0x00>;
				qcom,mdss-dsi-h-right-border = <0x00>;
				qcom,mdss-dsi-v-top-border = <0x00>;
				qcom,mdss-dsi-v-bottom-border = <0x00>;
				qcom,mdss-dsi-bpp = <0x18>;
				qcom,mdss-dsi-underflow-color = <0xff>;
				qcom,mdss-dsi-border-color = <0x00>;
				qcom,mdss-dsi-h-sync-pulse = <0x00>;
				qcom,mdss-dsi-traffic-mode = "burst_mode";
				qcom,mdss-dsi-bllp-eof-power-mode;
				qcom,mdss-dsi-bllp-power-mode;
				qcom,mdss-dsi-lane-0-state;
				qcom,mdss-dsi-lane-1-state;
				qcom,mdss-dsi-lane-2-state;
				qcom,mdss-dsi-lane-3-state;
				qcom,mdss-dsi-panel-timings = <0xe6382600 0x686e2a3c 0x44030400>;
				qcom,mdss-dsi-t-clk-post = <0x02>;
				qcom,mdss-dsi-t-clk-pre = <0x2d>;
				qcom,mdss-dsi-bl-min-level = <0x01>;
				qcom,mdss-dsi-bl-max-level = <0xfff>;
				qcom,mdss-dsi-dma-trigger = "trigger_sw";
				qcom,mdss-dsi-mdp-trigger = "none";
				qcom,mdss-dsi-on-command = [15 01 00 00 00 00 02 35 00 15 01 00 00 00 00 02 51 ff 15 01 00 00 00 00 02 53 2c 15 01 00 00 00 00 02 55 00 05 01 00 00 78 00 02 11 00 23 01 00 00 00 00 02 b0 00 29 01 00 00 00 00 07 b3 14 00 00 00 00 00 29 01 00 00 00 00 03 b6 3a d3 29 01 00 00 00 00 03 c0 00 00 29 01 00 00 00 00 23 c1 84 60 10 eb ff 6f ce ff ff 17 02 58 73 ae b1 20 c6 ff ff 1f f3 ff 5f 10 10 10 10 00 02 01 22 22 00 01 29 01 00 00 00 00 08 c2 31 f7 80 06 08 00 00 29 01 00 00 00 00 17 c4 70 00 00 00 00 04 00 00 00 0c 06 00 00 00 00 00 04 00 00 00 0c 06 29 01 00 00 00 00 29 c6 00 69 00 69 00 69 00 00 00 00 00 69 00 69 00 69 10 19 07 00 01 00 69 00 69 00 69 00 00 00 00 00 69 00 69 00 69 10 19 07 29 01 00 00 00 00 0a cb 31 fc 3f 8c 00 00 00 00 c0 23 01 00 00 00 00 02 cc 0b 29 01 00 00 00 00 0b d0 11 81 bb 1e 1e 4c 19 19 0c 00 29 01 00 00 00 00 1a d3 1b 33 bb bb b3 33 33 33 00 01 00 a0 d8 a0 0d 4e 4e 33 3b 22 72 07 3d bf 33 29 01 00 00 00 00 08 d5 06 00 00 01 51 01 32 29 01 00 00 00 00 1f c7 01 0a 11 18 26 33 3e 50 38 42 52 60 67 6e 77 01 0a 11 18 26 33 3e 50 38 42 52 60 67 6e 77 29 01 00 00 14 00 14 c8 01 00 00 00 00 fc 00 00 00 00 00 fc 00 00 00 00 00 fc 00 05 01 00 00 14 00 02 29 00];
				qcom,mdss-dsi-off-command = [05 01 00 00 14 00 02 28 00 05 01 00 00 78 00 02 10 00];
				qcom,mdss-dsi-on-command-state = "dsi_lp_mode";
				qcom,mdss-dsi-off-command-state = "dsi_lp_mode";
				qcom,mdss-dsi-bl-pmic-control-type = "bl_ctrl_pwm";
				qcom,mdss-dsi-reset-sequence = <0x01 0x0a 0x00 0x0a 0x01 0x0a>;
				qcom,mdss-dsi-tx-eot-append;
				qcom,mdss-dsi-post-init-delay = <0x01>;
				qcom,mdss-dsi-panel-timings-phy-v2 = <0x231e0809 0x50304a0 0x231e0809 0x50304a0 0x231e0809 0x50304a0 0x231e0809 0x50304a0 0x231a0809 0x50304a0>;
				qcom,esd-check-enabled;
				qcom,mdss-dsi-panel-status-check-mode = "reg_read";
				qcom,mdss-dsi-panel-status-command = <0x6010001 0x10a>;
				qcom,mdss-dsi-panel-status-command-state = "dsi_hs_mode";
				qcom,mdss-dsi-panel-status-value = <0x1c>;
				qcom,mdss-dsi-panel-on-check-value = <0x1c>;
				qcom,mdss-dsi-panel-status-read-length = <0x01>;
				qcom,mdss-dsi-panel-max-error-count = <0x03>;
				qcom,panel-supply-entries = <&dsi_panel_pwr_supply>;
				qcom,mdss-dsi-pan-enable-dynamic-fps;
				qcom,mdss-dsi-pan-fps-update = "dfps_immediate_porch_mode_vfp";
				qcom,mdss-dsi-bl-pmic-pwm-frequency = <0x64>;
				qcom,mdss-dsi-bl-pmic-bank-select = <0x00>;
				qcom,mdss-dsi-pwm-gpio = <&pm8953_gpios>, <0x08 0x00>;
			};
		};
	};

	fragment@12 {
		target = <&mdss_mdp>;

		__overlay__ {

			dsi_truly_1080_cmd: qcom,mdss_dsi_truly_1080p_cmd {
				qcom,mdss-dsi-panel-name = "truly 1080p cmd mode dsi panel";
				qcom,mdss-dsi-panel-type = "dsi_cmd_mode";
				qcom,mdss-dsi-panel-framerate = <0x3c>;
				qcom,mdss-dsi-virtual-channel-id = <0x00>;
				qcom,mdss-dsi-stream = <0x00>;
				qcom,mdss-dsi-panel-width = <0x438>;
				qcom,mdss-dsi-panel-height = <0x780>;
				qcom,mdss-dsi-h-front-porch = <0x60>;
				qcom,mdss-dsi-h-back-porch = <0x40>;
				qcom,mdss-dsi-h-pulse-width = <0x10>;
				qcom,mdss-dsi-h-sync-skew = <0x00>;
				qcom,mdss-dsi-v-back-porch = <0x10>;
				qcom,mdss-dsi-v-front-porch = <0x04>;
				qcom,mdss-dsi-v-pulse-width = <0x01>;
				qcom,mdss-dsi-h-left-border = <0x00>;
				qcom,mdss-dsi-h-right-border = <0x00>;
				qcom,mdss-dsi-v-top-border = <0x00>;
				qcom,mdss-dsi-v-bottom-border = <0x00>;
				qcom,mdss-dsi-bpp = <0x18>;
				qcom,mdss-dsi-underflow-color = <0xff>;
				qcom,mdss-dsi-border-color = <0x00>;
				qcom,mdss-dsi-te-pin-select = <0x01>;
				qcom,mdss-dsi-te-dcs-command = <0x01>;
				qcom,mdss-dsi-te-check-enable;
				qcom,mdss-dsi-te-using-te-pin;
				qcom,mdss-dsi-h-sync-pulse = <0x00>;
				qcom,mdss-dsi-traffic-mode = "burst_mode";
				qcom,mdss-dsi-bllp-eof-power-mode;
				qcom,mdss-dsi-bllp-power-mode;
				qcom,mdss-dsi-lane-0-state;
				qcom,mdss-dsi-lane-1-state;
				qcom,mdss-dsi-lane-2-state;
				qcom,mdss-dsi-lane-3-state;
				qcom,mdss-dsi-panel-timings = <0xe6382600 0x686e2a3c 0x44030400>;
				qcom,mdss-dsi-t-clk-post = <0x02>;
				qcom,mdss-dsi-t-clk-pre = <0x2d>;
				qcom,mdss-dsi-tx-eot-append;
				qcom,mdss-dsi-dma-trigger = "trigger_sw";
				qcom,mdss-dsi-mdp-trigger = "none";
				qcom,mdss-dsi-on-command = [23 01 00 00 00 00 02 d6 01 15 01 00 00 00 00 02 35 00 15 01 00 00 00 00 02 51 ff 15 01 00 00 00 00 02 53 2c 15 01 00 00 00 00 02 55 00 05 01 00 00 78 00 02 11 00 23 01 00 00 00 00 02 b0 04 29 01 00 00 00 00 07 b3 04 00 00 00 00 00 29 01 00 00 00 00 03 b6 3a d3 29 01 00 00 00 00 03 c0 00 00 29 01 00 00 00 00 23 c1 84 60 10 eb ff 6f ce ff ff 17 02 58 73 ae b1 20 c6 ff ff 1f f3 ff 5f 10 10 10 10 00 02 01 22 22 00 01 29 01 00 00 00 00 08 c2 31 f7 80 06 08 00 00 29 01 00 00 00 00 17 c4 70 00 00 00 00 04 00 00 00 0c 06 00 00 00 00 00 04 00 00 00 0c 06 29 01 00 00 00 00 29 c6 78 69 00 69 00 69 00 00 00 00 00 69 00 69 00 69 10 19 07 00 78 00 69 00 69 00 69 00 00 00 00 00 69 00 69 00 69 10 19 07 29 01 00 00 00 00 0a cb 31 fc 3f 8c 00 00 00 00 c0 23 01 00 00 00 00 02 cc 0b 29 01 00 00 00 00 0b d0 11 81 bb 1e 1e 4c 19 19 0c 00 29 01 00 00 00 00 1a d3 1b 33 bb bb b3 33 33 33 00 01 00 a0 d8 a0 0d 4e 4e 33 3b 22 72 07 3d bf 33 29 01 00 00 00 00 08 d5 06 00 00 01 51 01 32 29 01 00 00 00 00 1f c7 01 0a 11 18 26 33 3e 50 38 42 52 60 67 6e 77 01 0a 11 18 26 33 3e 50 38 42 52 60 67 6e 77 29 01 00 00 14 00 14 c8 01 00 00 00 00 fc 00 00 00 00 00 fc 00 00 00 00 00 fc 00 05 01 00 00 14 00 02 29 00];
				qcom,mdss-dsi-off-command = [05 01 00 00 14 00 02 28 00 05 01 00 00 78 00 02 10 00];
				qcom,mdss-dsi-on-command-state = "dsi_lp_mode";
				qcom,mdss-dsi-off-command-state = "dsi_lp_mode";
				qcom,mdss-dsi-bl-min-level = <0x01>;
				qcom,mdss-dsi-bl-max-level = <0xfff>;
				qcom,mdss-dsi-bl-pmic-control-type = "bl_ctrl_wled";
				qcom,mdss-dsi-reset-sequence = <0x01 0x0a 0x00 0x0a 0x01 0x0a>;
				qcom,mdss-dsi-post-init-delay = <0x01>;
				qcom,mdss-dsi-panel-timings-phy-v2 = <0x231e0809 0x50304a0 0x231e0809 0x50304a0 0x231e0809 0x50304a0 0x231e0809 0x50304a0 0x231a0809 0x50304a0>;
				qcom,esd-check-enabled;
				qcom,mdss-dsi-panel-status-check-mode = "reg_read";
				qcom,mdss-dsi-panel-status-command = <0x6010001 0x10a>;
				qcom,mdss-dsi-panel-status-command-state = "dsi_hs_mode";
				qcom,mdss-dsi-panel-status-value = <0x1c>;
				qcom,mdss-dsi-panel-on-check-value = <0x1c>;
				qcom,mdss-dsi-panel-status-read-length = <0x01>;
				qcom,mdss-dsi-panel-max-error-count = <0x03>;
				qcom,panel-supply-entries = <&dsi_panel_pwr_supply>;
				qcom,ulps-enabled;
				qcom,partial-update-enabled;
				qcom,panel-roi-alignment = <0x02 0x02 0x04 0x02 0x438 0x02>;
			};
		};
	};

	fragment@13 {
		target = <&mdss_mdp>;

		__overlay__ {

			dsi_adv7533_1080p: qcom,mdss_dsi_adv7533_1080p {
				label = "adv7533 1080p video mode dsi panel";
				qcom,mdss-dsi-panel-name = "dsi_adv7533_1080p";
				qcom,mdss-dsi-panel-controller = <&mdss_dsi0>;
				qcom,mdss-dsi-panel-type = "dsi_video_mode";
				qcom,mdss-dsi-panel-destination = "display_1";
				qcom,mdss-dsi-panel-framerate = <0x3c>;
				qcom,mdss-dsi-virtual-channel-id = <0x00>;
				qcom,mdss-dsi-stream = <0x00>;
				qcom,mdss-dsi-panel-width = <0x780>;
				qcom,mdss-dsi-panel-height = <0x438>;
				qcom,mdss-dsi-h-front-porch = <0x58>;
				qcom,mdss-dsi-h-back-porch = <0x94>;
				qcom,mdss-dsi-h-pulse-width = <0x2c>;
				qcom,mdss-dsi-h-sync-skew = <0x00>;
				qcom,mdss-dsi-v-back-porch = <0x24>;
				qcom,mdss-dsi-v-front-porch = <0x04>;
				qcom,mdss-dsi-v-pulse-width = <0x05>;
				qcom,mdss-dsi-h-left-border = <0x00>;
				qcom,mdss-dsi-h-right-border = <0x00>;
				qcom,mdss-dsi-v-top-border = <0x00>;
				qcom,mdss-dsi-v-bottom-border = <0x00>;
				qcom,mdss-dsi-bpp = <0x18>;
				qcom,mdss-dsi-underflow-color = <0xff>;
				qcom,mdss-dsi-border-color = <0x00>;
				qcom,mdss-dsi-on-command = [05 01 00 00 c8 00 02 11 00 05 01 00 00 0a 00 02 29 00];
				qcom,mdss-dsi-off-command = [05 01 00 00 00 00 02 28 00 05 01 00 00 00 00 02 10 00];
				qcom,mdss-dsi-on-command-state = "dsi_lp_mode";
				qcom,mdss-dsi-off-command-state = "dsi_hs_mode";
				qcom,mdss-dsi-h-sync-pulse = <0x01>;
				qcom,mdss-dsi-traffic-mode = "non_burst_sync_pulse";
				qcom,mdss-dsi-bllp-eof-power-mode;
				qcom,mdss-dsi-bllp-power-mode;
				qcom,mdss-dsi-lane-0-state;
				qcom,mdss-dsi-lane-1-state;
				qcom,mdss-dsi-lane-2-state;
				qcom,mdss-dsi-lane-3-state;
				qcom,mdss-dsi-panel-timings = <0xe6382600 0x686c2a3a 0x2c030400>;
				qcom,mdss-dsi-t-clk-post = <0x02>;
				qcom,mdss-dsi-t-clk-pre = <0x2b>;
				qcom,mdss-dsi-bl-min-level = <0x01>;
				qcom,mdss-dsi-bl-max-level = <0xfff>;
				qcom,mdss-dsi-dma-trigger = "trigger_sw";
				qcom,mdss-dsi-mdp-trigger = "none";
				qcom,mdss-dsi-reset-sequence = <0x01 0x14 0x00 0x01 0x01 0x14>;
				qcom,mdss-pan-physical-width-dimension = <0xa0>;
				qcom,mdss-pan-physical-height-dimension = <0x5a>;
				qcom,mdss-dsi-force-clock-lane-hs;
				qcom,mdss-dsi-always-on;
				qcom,mdss-dsi-panel-timings-phy-v2 = <0x241f0809 0x50304a0 0x241f0809 0x50304a0 0x241f0809 0x50304a0 0x241f0809 0x50304a0 0x241b0809 0x50304a0>;
				qcom,dba-panel;
				qcom,bridge-name = "adv7533";
			};
		};
	};

	fragment@14 {
		target = <&mdss_mdp>;

		__overlay__ {

			dsi_adv7533_720p: qcom,mdss_dsi_adv7533_720p {
				label = "adv7533 720p video mode dsi panel";
				qcom,mdss-dsi-panel-name = "dsi_adv7533_720p";
				qcom,mdss-dsi-panel-controller = <&mdss_dsi0>;
				qcom,mdss-dsi-panel-type = "dsi_video_mode";
				qcom,mdss-dsi-panel-destination = "display_1";
				qcom,mdss-dsi-panel-framerate = <0x3c>;
				qcom,mdss-dsi-virtual-channel-id = <0x00>;
				qcom,mdss-dsi-stream = <0x00>;
				qcom,mdss-dsi-panel-width = <0x500>;
				qcom,mdss-dsi-panel-height = <0x2d0>;
				qcom,mdss-dsi-h-front-porch = <0x6e>;
				qcom,mdss-dsi-h-back-porch = <0xdc>;
				qcom,mdss-dsi-h-pulse-width = <0x28>;
				qcom,mdss-dsi-h-sync-skew = <0x00>;
				qcom,mdss-dsi-v-back-porch = <0x14>;
				qcom,mdss-dsi-v-front-porch = <0x05>;
				qcom,mdss-dsi-v-pulse-width = <0x05>;
				qcom,mdss-dsi-h-left-border = <0x00>;
				qcom,mdss-dsi-h-right-border = <0x00>;
				qcom,mdss-dsi-v-top-border = <0x00>;
				qcom,mdss-dsi-v-bottom-border = <0x00>;
				qcom,mdss-dsi-bpp = <0x18>;
				qcom,mdss-dsi-underflow-color = <0xff>;
				qcom,mdss-dsi-border-color = <0x00>;
				qcom,mdss-dsi-on-command = [05 01 00 00 c8 00 02 11 00 05 01 00 00 0a 00 02 29 00];
				qcom,mdss-dsi-off-command = [05 01 00 00 00 00 02 28 00 05 01 00 00 00 00 02 10 00];
				qcom,mdss-dsi-on-command-state = "dsi_lp_mode";
				qcom,mdss-dsi-off-command-state = "dsi_hs_mode";
				qcom,mdss-dsi-h-sync-pulse = <0x01>;
				qcom,mdss-dsi-traffic-mode = "non_burst_sync_pulse";
				qcom,mdss-dsi-bllp-eof-power-mode;
				qcom,mdss-dsi-bllp-power-mode;
				qcom,mdss-dsi-lane-0-state;
				qcom,mdss-dsi-lane-1-state;
				qcom,mdss-dsi-lane-2-state;
				qcom,mdss-dsi-panel-timings = <0xa4241800 0x4e521c28 0x1c030400>;
				qcom,mdss-dsi-t-clk-post = <0x03>;
				qcom,mdss-dsi-t-clk-pre = <0x20>;
				qcom,mdss-dsi-bl-min-level = <0x01>;
				qcom,mdss-dsi-bl-max-level = <0xfff>;
				qcom,mdss-dsi-dma-trigger = "trigger_sw";
				qcom,mdss-dsi-mdp-trigger = "none";
				qcom,mdss-dsi-reset-sequence = <0x01 0x14 0x00 0x01 0x01 0x14>;
				qcom,mdss-pan-physical-width-dimension = <0xa0>;
				qcom,mdss-pan-physical-height-dimension = <0x5a>;
				qcom,mdss-dsi-force-clock-lane-hs;
				qcom,mdss-dsi-always-on;
				qcom,mdss-dsi-panel-timings-phy-v2 = <0x1e1b0406 0x20304a0 0x1e1b0406 0x20304a0 0x1e1b0406 0x20304a0 0x1e1b0406 0x20304a0 0x1e0e0405 0x20304a0>;
				qcom,dba-panel;
				qcom,bridge-name = "adv7533";
			};
		};
	};

	fragment@15 {
		target = <&mdss_mdp>;

		__overlay__ {

			dsi_r69006_1080p_video: qcom,mdss_dsi_r69006_1080p_video {
				qcom,mdss-dsi-panel-name = "r69006 1080p video mode dsi panel";
				qcom,mdss-dsi-panel-type = "dsi_video_mode";
				qcom,mdss-dsi-panel-framerate = <0x3c>;
				qcom,mdss-dsi-virtual-channel-id = <0x00>;
				qcom,mdss-dsi-stream = <0x00>;
				qcom,mdss-dsi-panel-width = <0x438>;
				qcom,mdss-dsi-panel-height = <0x780>;
				qcom,mdss-dsi-h-front-porch = <0x64>;
				qcom,mdss-dsi-h-back-porch = <0x52>;
				qcom,mdss-dsi-h-pulse-width = <0x14>;
				qcom,mdss-dsi-h-sync-skew = <0x00>;
				qcom,mdss-dsi-v-back-porch = <0x09>;
				qcom,mdss-dsi-v-front-porch = <0x03>;
				qcom,mdss-dsi-v-pulse-width = <0x0f>;
				qcom,mdss-dsi-h-left-border = <0x00>;
				qcom,mdss-dsi-h-right-border = <0x00>;
				qcom,mdss-dsi-v-top-border = <0x00>;
				qcom,mdss-dsi-v-bottom-border = <0x00>;
				qcom,mdss-dsi-bpp = <0x18>;
				qcom,mdss-dsi-underflow-color = <0xff>;
				qcom,mdss-dsi-border-color = <0x00>;
				qcom,mdss-dsi-on-command = [23 01 00 00 00 00 02 b0 00 29 01 00 00 00 00 06 b3 05 10 00 00 00 29 01 00 00 00 00 03 b4 0c 00 29 01 00 00 00 00 04 b6 3b c3 00 23 01 00 00 00 00 02 c0 00 15 01 00 00 00 00 02 36 98 23 01 00 00 00 00 02 cc 04 29 01 00 00 00 00 20 c1 84 00 10 ef 8b f1 ff ff df 9c c5 9a 73 8d ad 63 fe ff ff cb f8 01 00 aa 40 00 c2 01 08 00 01 29 01 00 00 00 00 0a cb 0d fe 1f 2c 00 00 00 00 00 29 01 00 00 00 00 0b c2 01 f7 80 04 63 00 60 00 01 30 29 01 00 00 00 00 07 c3 55 01 00 01 00 00 29 01 00 00 00 00 12 c4 70 00 00 00 00 00 00 00 00 02 01 00 05 01 00 00 00 29 01 00 00 00 00 0f c6 59 07 4a 07 4a 01 0e 01 02 01 02 09 15 07 29 01 00 00 00 00 1f c7 00 30 32 34 42 4e 56 62 44 4a 54 62 6b 73 7f 08 30 32 34 42 4e 56 62 44 4a 54 62 6b 73 7f 29 01 00 00 00 00 14 c8 00 00 00 00 00 fc 00 00 00 00 00 fc 00 00 00 00 00 fc 00 29 01 00 00 00 00 09 c9 1f 68 1f 68 4c 4c c4 11 29 01 00 00 00 00 11 d0 33 01 91 0b d9 19 19 00 00 00 19 99 00 00 00 00 29 01 00 00 00 00 1d d3 1b 3b bb ad a5 33 33 33 00 80 ad a8 6f 6f 33 33 33 f7 f2 1f 7d 7c ff 0f 99 00 ff ff 29 01 00 00 00 00 04 d4 57 33 03 29 01 00 00 00 00 0c d5 66 00 00 01 27 01 27 00 6d 00 6d 23 01 00 00 00 00 02 d6 81 05 01 00 00 78 00 02 11 00 05 01 00 00 78 00 02 29 00];
				qcom,mdss-dsi-off-command = [05 01 00 00 78 00 02 28 00 05 01 00 00 96 00 02 10 00];
				qcom,mdss-dsi-on-command-state = "dsi_lp_mode";
				qcom,mdss-dsi-off-command-state = "dsi_hs_mode";
				qcom,mdss-dsi-h-sync-pulse = <0x01>;
				qcom,mdss-dsi-traffic-mode = "burst_mode";
				qcom,mdss-dsi-bllp-eof-power-mode;
				qcom,mdss-dsi-bllp-power-mode;
				qcom,mdss-dsi-lane-0-state;
				qcom,mdss-dsi-lane-1-state;
				qcom,mdss-dsi-lane-2-state;
				qcom,mdss-dsi-lane-3-state;
				qcom,mdss-dsi-panel-timings = <0x7d251d00 0x37332227 0x1e030400>;
				qcom,mdss-dsi-t-clk-post = <0x20>;
				qcom,mdss-dsi-t-clk-pre = <0x2c>;
				qcom,mdss-dsi-bl-min-level = <0x01>;
				qcom,mdss-dsi-bl-max-level = <0xfff>;
				qcom,mdss-dsi-dma-trigger = "trigger_sw";
				qcom,mdss-dsi-mdp-trigger = "none";
				qcom,mdss-dsi-bl-pmic-control-type = "bl_ctrl_wled";
				qcom,mdss-dsi-reset-sequence = <0x01 0x14 0x00 0x02 0x01 0x14>;
				qcom,mdss-dsi-panel-status-command = <0x6010001 0x500010a>;
				qcom,mdss-dsi-panel-status-command-mode = "dsi_lp_mode";
				qcom,mdss-dsi-panel-status-check-mode = "reg_read";
				qcom,mdss-dsi-panel-status-read-length = <0x01>;
				qcom,mdss-dsi-panel-status-value = <0x1c>;
				qcom,mdss-dsi-panel-max-error-count = <0x03>;
				qcom,mdss-dsi-panel-timings-phy-v2 = <0x241f0809 0x50304a0 0x241f0809 0x50304a0 0x241f0809 0x50304a0 0x241f0809 0x50304a0 0x241b0809 0x50304a0>;
			};
		};
	};

	fragment@16 {
		target = <&mdss_mdp>;

		__overlay__ {

			dsi_r69006_1080p_cmd: qcom,mdss_dsi_r69006_1080p_cmd {
				qcom,mdss-dsi-panel-name = "r69006 1080p cmd mode dsi panel";
				qcom,mdss-dsi-panel-type = "dsi_cmd_mode";
				qcom,mdss-dsi-panel-framerate = <0x3c>;
				qcom,mdss-dsi-virtual-channel-id = <0x00>;
				qcom,mdss-dsi-stream = <0x00>;
				qcom,mdss-dsi-panel-width = <0x438>;
				qcom,mdss-dsi-panel-height = <0x780>;
				qcom,mdss-dsi-h-front-porch = <0x64>;
				qcom,mdss-dsi-h-back-porch = <0x52>;
				qcom,mdss-dsi-h-pulse-width = <0x14>;
				qcom,mdss-dsi-h-sync-skew = <0x00>;
				qcom,mdss-dsi-v-back-porch = <0x09>;
				qcom,mdss-dsi-v-front-porch = <0x03>;
				qcom,mdss-dsi-v-pulse-width = <0x0f>;
				qcom,mdss-dsi-h-left-border = <0x00>;
				qcom,mdss-dsi-h-right-border = <0x00>;
				qcom,mdss-dsi-v-top-border = <0x00>;
				qcom,mdss-dsi-v-bottom-border = <0x00>;
				qcom,mdss-dsi-bpp = <0x18>;
				qcom,mdss-dsi-underflow-color = <0xff>;
				qcom,mdss-dsi-border-color = <0x00>;
				qcom,mdss-dsi-on-command = [23 01 00 00 00 00 02 b0 00 29 01 00 00 00 00 06 b3 04 10 00 00 00 29 01 00 00 00 00 03 b4 0c 00 29 01 00 00 00 00 04 b6 3b d3 00 23 01 00 00 00 00 02 c0 00 15 01 00 00 00 00 02 36 98 23 01 00 00 00 00 02 cc 04 29 01 00 00 00 00 20 c1 84 00 10 ef 8b f1 ff ff df 9c c5 9a 73 8d ad 63 fe ff ff cb f8 01 00 aa 40 02 c2 01 08 00 01 29 01 00 00 00 00 0a cb 0d fe 1f 2c 00 00 00 00 00 29 01 00 00 00 00 0b c2 01 f7 80 04 63 00 60 00 01 30 29 01 00 00 00 00 07 c3 55 01 00 01 00 00 29 01 00 00 00 00 12 c4 70 00 00 00 00 00 00 00 00 02 01 00 05 01 00 00 00 29 01 00 00 00 00 0f c6 57 07 4a 07 4a 01 0e 01 02 01 02 09 15 07 29 01 00 00 00 00 1f c7 00 06 0c 16 27 35 3f 4d 33 3c 49 5b 64 66 67 00 06 0c 16 27 35 3f 4d 33 3c 49 5b 64 66 67 29 01 00 00 00 00 14 c8 00 00 fe 01 08 e7 00 00 fd 02 03 a8 00 00 fc e7 e9 c9 00 29 01 00 00 00 00 09 c9 1f 68 1f 68 4c 4c c4 11 29 01 00 00 00 00 11 d0 11 01 91 0b d9 19 19 00 00 00 19 99 00 00 00 00 29 01 00 00 00 00 1d d3 1b 3b bb ad a5 33 33 33 00 80 ad a8 37 33 33 33 33 f7 f2 1f 7d 7c ff 0f 99 00 ff ff 29 01 00 00 00 00 04 d4 57 33 03 29 01 00 00 00 00 0c d5 66 00 00 01 32 01 32 00 0b 00 0b 29 01 00 00 00 00 02 be 04 29 01 00 00 00 00 11 cf 40 10 00 00 00 00 32 00 00 00 00 00 00 00 00 00 29 01 00 00 00 00 06 de 00 00 3f ff 10 29 01 00 00 00 00 02 e9 00 29 01 00 00 00 00 02 f2 00 23 01 00 00 00 00 02 d6 01 39 01 00 00 00 00 02 35 00 39 01 00 00 00 00 02 51 ff 39 01 00 00 00 00 02 53 2c 39 01 00 00 00 00 02 55 00 05 01 00 00 78 00 02 11 00 05 01 00 00 14 00 02 29 00];
				qcom,mdss-dsi-off-command = [05 01 00 00 0a 00 02 28 00 29 01 00 00 00 00 1d d3 13 3b bb a5 a5 33 33 33 00 80 a4 a8 37 33 33 33 33 f7 f2 1f 7d 7c ff 0f 99 00 ff ff 05 01 00 00 5a 00 02 10 00];
				qcom,mdss-dsi-on-command-state = "dsi_lp_mode";
				qcom,mdss-dsi-off-command-state = "dsi_hs_mode";
				qcom,mdss-dsi-traffic-mode = "burst_mode";
				qcom,mdss-dsi-bllp-eof-power-mode;
				qcom,mdss-dsi-bllp-power-mode;
				qcom,mdss-dsi-lane-0-state;
				qcom,mdss-dsi-lane-1-state;
				qcom,mdss-dsi-lane-2-state;
				qcom,mdss-dsi-lane-3-state;
				qcom,mdss-dsi-te-pin-select = <0x01>;
				qcom,mdss-dsi-wr-mem-start = <0x2c>;
				qcom,mdss-dsi-wr-mem-continue = <0x3c>;
				qcom,mdss-dsi-te-dcs-command = <0x01>;
				qcom,mdss-dsi-te-check-enable;
				qcom,mdss-dsi-te-using-te-pin;
				qcom,mdss-dsi-panel-timings = <0x6e3f3600 0x5a4f3841 0x54030400>;
				qcom,mdss-dsi-t-clk-post = <0x1e>;
				qcom,mdss-dsi-t-clk-pre = <0x30>;
				qcom,mdss-dsi-bl-min-level = <0x01>;
				qcom,mdss-dsi-bl-max-level = <0xfff>;
				qcom,mdss-dsi-dma-trigger = "trigger_sw";
				qcom,mdss-dsi-mdp-trigger = "none";
				qcom,mdss-dsi-bl-pmic-control-type = "bl_ctrl_wled";
				qcom,mdss-dsi-reset-sequence = <0x01 0x0a 0x00 0x0a 0x01 0x0a>;
				qcom,mdss-dsi-panel-status-command = <0x6010001 0x500010a>;
				qcom,mdss-dsi-panel-status-command-mode = "dsi_lp_mode";
				qcom,mdss-dsi-panel-status-check-mode = "reg_read";
				qcom,mdss-dsi-panel-status-read-length = <0x01>;
				qcom,mdss-dsi-panel-status-value = <0x1c>;
				qcom,mdss-dsi-panel-max-error-count = <0x03>;
				qcom,mdss-dsi-rx-eot-ignore;
				qcom,mdss-dsi-tx-eot-append;
				qcom,mdss-dsi-panel-timings-phy-v2 = <0x241f0809 0x50304a0 0x241f0809 0x50304a0 0x241f0809 0x50304a0 0x241f0809 0x50304a0 0x241b0809 0x50304a0>;
			};
		};
	};

	fragment@17 {
		target = <&mdss_mdp>;

		__overlay__ {

			dsi_truly_wuxga_vid: qcom,mdss_dsi_truly_wuxga_video {
				qcom,mdss-dsi-panel-name = "truly wuxga video mode dsi panel";
				qcom,mdss-dsi-panel-type = "dsi_video_mode";
				qcom,mdss-dsi-panel-framerate = <0x3c>;
				qcom,mdss-dsi-virtual-channel-id = <0x00>;
				qcom,mdss-dsi-stream = <0x00>;
				qcom,mdss-dsi-panel-width = <0x780>;
				qcom,mdss-dsi-panel-height = <0x4b0>;
				qcom,mdss-dsi-h-front-porch = <0x60>;
				qcom,mdss-dsi-h-back-porch = <0x40>;
				qcom,mdss-dsi-h-pulse-width = <0x10>;
				qcom,mdss-dsi-h-sync-skew = <0x00>;
				qcom,mdss-dsi-v-back-porch = <0x10>;
				qcom,mdss-dsi-v-front-porch = <0x04>;
				qcom,mdss-dsi-v-pulse-width = <0x01>;
				qcom,mdss-dsi-h-left-border = <0x00>;
				qcom,mdss-dsi-h-right-border = <0x00>;
				qcom,mdss-dsi-v-top-border = <0x00>;
				qcom,mdss-dsi-v-bottom-border = <0x00>;
				qcom,mdss-dsi-bpp = <0x18>;
				qcom,mdss-dsi-underflow-color = <0xff>;
				qcom,mdss-dsi-border-color = <0x00>;
				qcom,mdss-dsi-h-sync-pulse = <0x00>;
				qcom,mdss-dsi-traffic-mode = "burst_mode";
				qcom,mdss-dsi-bllp-eof-power-mode;
				qcom,mdss-dsi-bllp-power-mode;
				qcom,mdss-dsi-lane-0-state;
				qcom,mdss-dsi-lane-1-state;
				qcom,mdss-dsi-lane-2-state;
				qcom,mdss-dsi-lane-3-state;
				qcom,mdss-dsi-panel-timings = <0xf33a2600 0x6c6e2c3e 0x2f030400>;
				qcom,mdss-dsi-t-clk-post = <0x02>;
				qcom,mdss-dsi-t-clk-pre = <0x2d>;
				qcom,mdss-dsi-bl-min-level = <0x01>;
				qcom,mdss-dsi-bl-max-level = <0xfff>;
				qcom,mdss-dsi-dma-trigger = "trigger_sw";
				qcom,mdss-dsi-mdp-trigger = "none";
				qcom,mdss-dsi-on-command = [32 01 00 00 00 00 02 00 00];
				qcom,mdss-dsi-off-command = [22 01 00 00 00 00 02 00 00];
				qcom,mdss-dsi-on-command-state = "dsi_hs_mode";
				qcom,mdss-dsi-off-command-state = "dsi_lp_mode";
				qcom,mdss-dsi-bl-pmic-control-type = "bl_ctrl_wled";
				qcom,mdss-dsi-reset-sequence = <0x01 0xc8 0x00 0xc8 0x01 0xc8>;
				qcom,mdss-dsi-panel-timings-phy-v2 = <0x241f0809 0x50304a0 0x241f0809 0x50304a0 0x241f0809 0x50304a0 0x241f0809 0x50304a0 0x241c0809 0x50304a0>;
			};
		};
	};

	fragment@18 {
		target = <&mdss_mdp>;

		__overlay__ {

			dsi_lt8912_480_vid: qcom,mdss_dsi_lt8912_480p_video {
				qcom,mdss-dsi-panel-name = "lt8912 480p video mode dsi panel";
				qcom,mdss-dsi-panel-type = "dsi_video_mode";
				qcom,mdss-dsi-panel-destination = "display_1";
				qcom,mdss-dsi-color-order = "rgb_swap_rgb";
				qcom,mdss-dsi-lane-map = "lane_map_0123";
				qcom,mdss-dsi-panel-framerate = <0x3c>;
				qcom,mdss-dsi-virtual-channel-id = <0x00>;
				qcom,mdss-dsi-stream = <0x00>;
				qcom,mdss-dsi-panel-width = <0x280>;
				qcom,mdss-dsi-panel-height = <0x1e0>;
				qcom,mdss-dsi-h-front-porch = <0x10>;
				qcom,mdss-dsi-h-back-porch = <0x30>;
				qcom,mdss-dsi-h-pulse-width = <0x60>;
				qcom,mdss-dsi-h-sync-skew = <0x00>;
				qcom,mdss-dsi-v-back-porch = <0x20>;
				qcom,mdss-dsi-v-front-porch = <0x0f>;
				qcom,mdss-dsi-v-pulse-width = <0x02>;
				qcom,mdss-dsi-h-left-border = <0x00>;
				qcom,mdss-dsi-h-right-border = <0x00>;
				qcom,mdss-dsi-v-top-border = <0x00>;
				qcom,mdss-dsi-v-bottom-border = <0x00>;
				qcom,mdss-dsi-bpp = <0x18>;
				qcom,mdss-dsi-underflow-color = <0xff>;
				qcom,mdss-dsi-border-color = <0x00>;
				qcom,mdss-dsi-on-command = [05 01 00 00 a0 00 02 11 00 05 01 00 00 a0 00 02 29 00];
				qcom,mdss-dsi-off-command = [05 01 00 00 78 00 02 28 00 05 01 00 00 78 00 02 10 00];
				qcom,mdss-dsi-on-command-state = "dsi_lp_mode";
				qcom,mdss-dsi-off-command-state = "dsi_lp_mode";
				qcom,mdss-dsi-h-sync-pulse = <0x00>;
				qcom,mdss-dsi-traffic-mode = "non_burst_sync_event";
				qcom,mdss-dsi-bllp-eof-power-mode;
				qcom,mdss-dsi-bllp-power-mode;
				qcom,mdss-dsi-lane-0-state;
				qcom,mdss-dsi-lane-1-state;
				qcom,mdss-dsi-panel-timings-phy-v2 = <0x1d1a0305 0x10304a0 0x1d1a0305 0x10304a0 0x1d0a0304 0x10304a0>;
				qcom,mdss-dsi-panel-timings = <0x65120c00 0x34381016 0xf030400>;
				qcom,mdss-dsi-t-clk-post = <0x02>;
				qcom,mdss-dsi-t-clk-pre = <0x2b>;
				qcom,mdss-dsi-dma-trigger = "trigger_sw";
				qcom,mdss-dsi-mdp-trigger = "none";
				qcom,mdss-dsi-reset-sequence = <0x01 0x14 0x00 0x02 0x01 0x14>;
				qcom,mdss-dsi-post-init-delay = <0x01>;
				qcom,mdss-dsi-force-clock-lane-hs;
			};
		};
	};

	fragment@19 {
		target = <&mdss_mdp>;

		__overlay__ {

			dsi_lt8912_1080_vid: qcom,mdss_dsi_lt8912_1080p_video {
				qcom,mdss-dsi-panel-name = "lt8912 1080p video mode dsi panel";
				qcom,mdss-dsi-panel-type = "dsi_video_mode";
				qcom,mdss-dsi-panel-destination = "display_1";
				qcom,mdss-dsi-color-order = "rgb_swap_rgb";
				qcom,mdss-dsi-lane-map = "lane_map_0123";
				qcom,mdss-dsi-panel-framerate = <0x3c>;
				qcom,mdss-dsi-virtual-channel-id = <0x00>;
				qcom,mdss-dsi-stream = <0x00>;
				qcom,mdss-dsi-panel-width = <0x780>;
				qcom,mdss-dsi-panel-height = <0x438>;
				qcom,mdss-dsi-h-front-porch = <0x58>;
				qcom,mdss-dsi-h-back-porch = <0x94>;
				qcom,mdss-dsi-h-pulse-width = <0x2c>;
				qcom,mdss-dsi-h-sync-skew = <0x00>;
				qcom,mdss-dsi-v-back-porch = <0x24>;
				qcom,mdss-dsi-v-front-porch = <0x04>;
				qcom,mdss-dsi-v-pulse-width = <0x05>;
				qcom,mdss-dsi-h-left-border = <0x00>;
				qcom,mdss-dsi-h-right-border = <0x00>;
				qcom,mdss-dsi-v-top-border = <0x00>;
				qcom,mdss-dsi-v-bottom-border = <0x00>;
				qcom,mdss-dsi-bpp = <0x18>;
				qcom,mdss-dsi-underflow-color = <0xff>;
				qcom,mdss-dsi-border-color = <0x00>;
				qcom,mdss-dsi-on-command = [05 01 00 00 a0 00 02 11 00 05 01 00 00 a0 00 02 29 00];
				qcom,mdss-dsi-off-command = [05 01 00 00 78 00 02 28 00 05 01 00 00 78 00 02 10 00];
				qcom,mdss-dsi-on-command-state = "dsi_lp_mode";
				qcom,mdss-dsi-off-command-state = "dsi_lp_mode";
				qcom,mdss-dsi-h-sync-pulse = <0x00>;
				qcom,mdss-dsi-traffic-mode = "non_burst_sync_event";
				qcom,mdss-dsi-bllp-eof-power-mode;
				qcom,mdss-dsi-bllp-power-mode;
				qcom,mdss-dsi-lane-0-state;
				qcom,mdss-dsi-lane-1-state;
				qcom,mdss-dsi-panel-timings-phy-v2 = <0x231e0809 0x50304a0 0x231e0809 0x50304a0 0x231e0809 0x50304a0 0x231e0809 0x50304a0 0x231a0809 0x50304a0>;
				qcom,mdss-dsi-panel-timings = <0xe6382600 0x686c2a3a 0x2c030400>;
				qcom,mdss-dsi-t-clk-post = <0x02>;
				qcom,mdss-dsi-t-clk-pre = <0x2b>;
				qcom,mdss-dsi-dma-trigger = "trigger_sw";
				qcom,mdss-dsi-mdp-trigger = "none";
				qcom,mdss-dsi-reset-sequence = <0x01 0x14 0x00 0x02 0x01 0x14>;
				qcom,mdss-dsi-post-init-delay = <0x01>;
				qcom,mdss-dsi-force-clock-lane-hs;
			};
		};
	};

	fragment@20 {
		target = <&mdss_mdp>;

		__overlay__ {

			dsi_hx8399c_truly_vid: qcom,mdss_dsi_hx8399c_truly_video {
				qcom,mdss-dsi-panel-name = "hx8399c video mode dsi truly panel";
				qcom,mdss-dsi-panel-type = "dsi_video_mode";
				qcom,mdss-dsi-panel-framerate = <0x3c>;
				qcom,mdss-dsi-virtual-channel-id = <0x00>;
				qcom,mdss-dsi-stream = <0x00>;
				qcom,mdss-dsi-panel-width = <0x438>;
				qcom,mdss-dsi-panel-height = <0x870>;
				qcom,mdss-dsi-h-front-porch = <0x34>;
				qcom,mdss-dsi-h-back-porch = <0x30>;
				qcom,mdss-dsi-h-pulse-width = <0x08>;
				qcom,mdss-dsi-h-sync-skew = <0x00>;
				qcom,mdss-dsi-v-back-porch = <0x08>;
				qcom,mdss-dsi-v-front-porch = <0x08>;
				qcom,mdss-dsi-v-pulse-width = <0x04>;
				qcom,mdss-dsi-h-left-border = <0x00>;
				qcom,mdss-dsi-h-right-border = <0x00>;
				qcom,mdss-dsi-v-top-border = <0x00>;
				qcom,mdss-dsi-v-bottom-border = <0x00>;
				qcom,mdss-pan-physical-width-dimension = <0x41>;
				qcom,mdss-pan-physical-height-dimension = <0x81>;
				qcom,mdss-dsi-bpp = <0x18>;
				qcom,mdss-dsi-color-order = "rgb_swap_rgb";
				qcom,mdss-dsi-underflow-color = <0xff>;
				qcom,mdss-dsi-border-color = <0x00>;
				qcom,mdss-dsi-on-command = [39 01 00 00 00 00 04 b9 ff 83 99 39 01 00 00 00 00 02 d2 88 39 01 00 00 00 00 0c b1 02 04 72 92 01 32 aa 11 11 52 57 39 01 00 00 00 00 10 b2 00 80 80 cc 05 07 5a 11 10 10 00 1e 70 03 d4 39 01 00 00 00 00 2d b4 00 ff 59 59 01 ab 00 00 09 00 03 05 00 28 03 0b 0d 21 03 02 00 0c a3 80 59 59 02 ab 00 00 09 00 03 05 00 28 03 0b 0d 02 00 0c a3 01 39 01 00 00 05 00 22 d3 00 0c 03 03 00 00 10 10 00 00 03 00 03 00 08 78 08 78 00 00 00 00 00 24 02 05 05 03 00 00 00 05 40 39 01 00 00 05 00 21 d5 20 20 19 19 18 18 02 03 00 01 24 24 18 18 18 18 24 24 00 00 00 00 00 00 00 00 2f 2f 30 30 31 31 39 01 00 00 05 00 21 d6 24 24 18 18 19 19 01 00 03 02 24 24 18 18 18 18 20 20 40 40 40 40 40 40 40 40 2f 2f 30 30 31 31 39 01 00 00 00 00 02 bd 00 39 01 00 00 00 00 11 d8 aa aa aa aa aa aa aa aa aa ba aa aa aa ba aa aa 39 01 00 00 00 00 02 bd 01 39 01 00 00 00 00 11 d8 00 00 00 00 00 00 00 00 82 ea aa aa 82 ea aa aa 39 01 00 00 00 00 02 bd 02 39 01 00 00 00 00 09 d8 ff ff c0 3f ff ff c0 3f 39 01 00 00 00 00 02 bd 00 39 01 00 00 05 00 37 e0 01 21 31 2d 66 6f 7b 75 7a 81 86 89 8c 90 95 97 9a a1 a2 aa 9e ad b0 5b 57 63 7a 01 21 31 2d 66 6f 7b 75 7a 81 86 89 8c 90 95 97 9a a1 a2 aa 9e ad b0 5b 57 63 7a 39 01 00 00 00 00 03 b6 7e 7e 39 01 00 00 00 00 02 cc 08 05 01 00 00 96 00 02 11 00 05 01 00 00 32 00 02 29 00];
				qcom,mdss-dsi-off-command = [05 01 00 00 32 00 02 28 00 05 01 00 00 96 00 02 10 00];
				qcom,mdss-dsi-on-command-state = "dsi_lp_mode";
				qcom,mdss-dsi-off-command-state = "dsi_hs_mode";
				qcom,mdss-dsi-h-sync-pulse = <0x00>;
				qcom,mdss-dsi-traffic-mode = "non_burst_sync_event";
				qcom,mdss-dsi-lane-map = "lane_map_0123";
				qcom,mdss-dsi-bllp-eof-power-mode;
				qcom,mdss-dsi-bllp-power-mode;
				qcom,mdss-dsi-tx-eot-append;
				qcom,mdss-dsi-lane-0-state;
				qcom,mdss-dsi-lane-1-state;
				qcom,mdss-dsi-lane-2-state;
				qcom,mdss-dsi-lane-3-state;
				qcom,mdss-dsi-t-clk-post = <0x0e>;
				qcom,mdss-dsi-t-clk-pre = <0x31>;
				qcom,mdss-dsi-dma-trigger = "trigger_sw";
				qcom,mdss-dsi-mdp-trigger = "none";
				qcom,mdss-dsi-lp11-init;
				qcom,mdss-dsi-reset-sequence = <0x01 0x0a 0x00 0x0a 0x01 0x0a>;
				qcom,mdss-dsi-panel-timings-phy-v2 = <0x241f0809 0x50304a0 0x241f0809 0x50304a0 0x241f0809 0x50304a0 0x241f0809 0x50304a0 0x241c0809 0x50304a0>;
				qcom,esd-check-enabled;
				qcom,mdss-dsi-panel-status-check-mode = "reg_read";
				qcom,mdss-dsi-panel-status-command = <0x6010001 0x10a>;
				qcom,mdss-dsi-panel-status-command-state = "dsi_lp_mode";
				qcom,mdss-dsi-panel-status-value = <0x9d 0x9d 0x9d 0x9d>;
				qcom,mdss-dsi-panel-on-check-value = <0x9d 0x9d 0x9d 0x9d>;
				qcom,mdss-dsi-panel-status-read-length = <0x04>;
				qcom,mdss-dsi-panel-max-error-count = <0x03>;
				qcom,mdss-dsi-min-refresh-rate = <0x30>;
				qcom,mdss-dsi-max-refresh-rate = <0x3c>;
				qcom,mdss-dsi-pan-enable-dynamic-fps;
				qcom,mdss-dsi-pan-fps-update = "dfps_immediate_porch_mode_vfp";
				qcom,panel-supply-entries = <&dsi_panel_pwr_supply>;
				qcom,mdss-dsi-bl-pmic-control-type = "bl_ctrl_pwm";
				qcom,mdss-dsi-bl-pmic-pwm-frequency = <0x64>;
				qcom,mdss-dsi-bl-pmic-bank-select = <0x00>;
				qcom,mdss-dsi-pwm-gpio = <&pm8953_gpios>, <0x08 0x00>;
			};
		};
	};

	fragment@21 {
		target = <&mdss_mdp>;

		__overlay__ {

			dsi_hx8399c_hd_vid: qcom,mdss_dsi_hx8399c_hd_video {
				qcom,mdss-dsi-panel-name = "hx8399c video mode dsi hd panel";
				qcom,mdss-dsi-panel-type = "dsi_video_mode";
				qcom,mdss-dsi-panel-framerate = <0x3c>;
				qcom,mdss-dsi-virtual-channel-id = <0x00>;
				qcom,mdss-dsi-stream = <0x00>;
				qcom,mdss-dsi-panel-width = <0x2d0>;
				qcom,mdss-dsi-panel-height = <0x5a0>;
				qcom,mdss-dsi-h-front-porch = <0x30>;
				qcom,mdss-dsi-h-back-porch = <0x30>;
				qcom,mdss-dsi-h-pulse-width = <0x10>;
				qcom,mdss-dsi-h-sync-skew = <0x00>;
				qcom,mdss-dsi-v-back-porch = <0x28>;
				qcom,mdss-dsi-v-front-porch = <0x24>;
				qcom,mdss-dsi-v-pulse-width = <0x04>;
				qcom,mdss-dsi-h-left-border = <0x00>;
				qcom,mdss-dsi-h-right-border = <0x00>;
				qcom,mdss-dsi-v-top-border = <0x00>;
				qcom,mdss-dsi-v-bottom-border = <0x00>;
				qcom,mdss-dsi-bpp = <0x18>;
				qcom,mdss-dsi-color-order = "rgb_swap_rgb";
				qcom,mdss-dsi-underflow-color = <0xff>;
				qcom,mdss-dsi-border-color = <0x00>;
				qcom,mdss-dsi-on-command = <0x39010000 0x4b9 0xff839939 0x1000000 0x2d288 0x39010000 0xcb1 0x2047292 0x132aa11 0x11525739 0x1000000 0x10b200 0x8080cc05 0x75a1110 0x10001e70 0x3d43901 0x00 0x2db400ff 0x595901ab 0x900 0x3050028 0x30b0d21 0x302000c 0xa3805959 0x2ab0000 0x9000305 0x28030b 0xd02000c 0xa3013901 0x500 0x22d3000c 0x3030000 0x10100000 0x3000300 0x8780878 0x00 0x240205 0x5030000 0x54039 0x1000005 0x21d520 0x20191918 0x18020300 0x1242418 0x18181824 0x24000000 0x00 0x2f2f30 0x30313139 0x1000005 0x21d624 0x24181819 0x19010003 0x2242418 0x18181820 0x20404040 0x40404040 0x402f2f30 0x30313139 0x1000000 0x2bd00 0x39010000 0x11d8 0xaaaaaaaa 0xaaaaaaaa 0xaabaaaaa 0xaabaaaaa 0x39010000 0x2bd 0x1390100 0x11 0xd8000000 0x00 0x82eaaa 0xaa82eaaa 0xaa390100 0x02 0xbd023901 0x00 0x9d8ffff 0xc03fffff 0xc03f3901 0x00 0x2bd0039 0x1000005 0x37e001 0x21312d66 0x6f7b757a 0x8186898c 0x9095979a 0xa1a2aa9e 0xadb05b57 0x637a0121 0x312d666f 0x7b757a81 0x86898c90 0x95979aa1 0xa2aa9ead 0xb05b5763 0x7a390100 0x03 0xb67e7e39 0x1000000 0x2cc08 0x39010000 0x235 0x390100 0x02 0xdd030501 0x9600 0x2110005 0x1000014 0x22900>;
				qcom,mdss-dsi-off-command = [05 01 00 00 14 00 02 28 00 05 01 00 00 78 00 02 10 00];
				qcom,mdss-dsi-on-command-state = "dsi_lp_mode";
				qcom,mdss-dsi-off-command-state = "dsi_hs_mode";
				qcom,mdss-dsi-h-sync-pulse = <0x00>;
				qcom,mdss-dsi-traffic-mode = "non_burst_sync_event";
				qcom,mdss-dsi-lane-map = "lane_map_0123";
				qcom,mdss-dsi-bllp-eof-power-mode;
				qcom,mdss-dsi-bllp-power-mode;
				qcom,mdss-dsi-tx-eot-append;
				qcom,mdss-dsi-lane-0-state;
				qcom,mdss-dsi-lane-1-state;
				qcom,mdss-dsi-lane-2-state;
				qcom,mdss-dsi-lane-3-state;
				qcom,mdss-dsi-panel-timings = <0x7a1a1200 0x3e42161e 0x14030400>;
				qcom,mdss-dsi-t-clk-post = <0x0a>;
				qcom,mdss-dsi-t-clk-pre = <0x1d>;
				qcom,mdss-dsi-dma-trigger = "trigger_sw";
				qcom,mdss-dsi-mdp-trigger = "none";
				qcom,mdss-dsi-lp11-init;
				qcom,mdss-dsi-reset-sequence = <0x01 0x0a 0x00 0x0a 0x01 0x0a>;
				qcom,mdss-dsi-panel-timings-phy-v2 = <0x241f0809 0x50304a0 0x241f0809 0x50304a0 0x241f0809 0x50304a0 0x241f0809 0x50304a0 0x241c0809 0x50304a0>;
				qcom,esd-check-enabled;
				qcom,mdss-dsi-panel-status-check-mode = "reg_read";
				qcom,mdss-dsi-panel-status-command = <0x6010001 0x10a>;
				qcom,mdss-dsi-panel-status-command-state = "dsi_lp_mode";
				qcom,mdss-dsi-panel-status-value = <0x9d 0x9d 0x9d 0x9d>;
				qcom,mdss-dsi-panel-on-check-value = <0x9d 0x9d 0x9d 0x9d>;
				qcom,mdss-dsi-panel-status-read-length = <0x04>;
				qcom,mdss-dsi-panel-max-error-count = <0x03>;
				qcom,mdss-dsi-min-refresh-rate = <0x37>;
				qcom,mdss-dsi-max-refresh-rate = <0x3c>;
				qcom,mdss-dsi-pan-enable-dynamic-fps;
				qcom,mdss-dsi-pan-fps-update = "dfps_immediate_porch_mode_vfp";
				qcom,panel-supply-entries = <&dsi_panel_pwr_supply>;
			};
		};
	};

	fragment@22 {
		target = <&soc>;

		__overlay__ {

			dsi_panel_pwr_supply: dsi_panel_pwr_supply {
				#address-cells = <0x01>;
				#size-cells = <0x00>;

				qcom,panel-supply-entry@0 {
					reg = <0x01>;
					qcom,supply-name = "vddio";
					qcom,supply-min-voltage = <0x1b7740>;
					qcom,supply-max-voltage = <0x1b7740>;
					qcom,supply-enable-load = <0x186a0>;
					qcom,supply-disable-load = <0x64>;
				};

				qcom,panel-supply-entry@1 {
					reg = <0x02>;
					qcom,supply-name = "lab";
					qcom,supply-min-voltage = <0x4630c0>;
					qcom,supply-max-voltage = <0x5b8d80>;
					qcom,supply-enable-load = <0x186a0>;
					qcom,supply-disable-load = <0x64>;
				};

				qcom,panel-supply-entry@2 {
					reg = <0x03>;
					qcom,supply-name = "ibb";
					qcom,supply-min-voltage = <0x4630c0>;
					qcom,supply-max-voltage = <0x5b8d80>;
					qcom,supply-enable-load = <0x186a0>;
					qcom,supply-disable-load = <0x64>;
					qcom,supply-post-on-sleep = <0x0a>;
				};
			};
		};
	};

	fragment@23 {
		target = <&mdss_mdp>;

		__overlay__ {
			qcom,mdss-pref-prim-intf = "dsi";
		};
	};

	fragment@24 {
		target = <&mdss_dsi>;

		__overlay__ {
			hw-config = "single_dsi";
		};
	};

	fragment@25 {
		target = <&mdss_dsi0>;

		__overlay__ {
			qcom,dsi-pref-prim-pan = <&dsi_truly_1080_vid>;
			pinctrl-names = "mdss_default", "mdss_sleep";
			pinctrl-0 = <&mdss_dsi_active>, <&mdss_te_active>;
			pinctrl-1 = <&mdss_dsi_suspend>, <&mdss_te_suspend>;
			qcom,platform-te-gpio = <&tlmm>, <0x18 0x00>;
			qcom,platform-reset-gpio = <&tlmm>, <0x3d 0x00>;
			qcom,platform-bklight-en-gpio = <&tlmm>, <0x3b 0x00>;
		};
	};

	fragment@26 {
		target = <&mdss_dsi1>;

		__overlay__ {
			status = "disabled";
			qcom,dsi-pref-prim-pan = <&dsi_adv7533_1080p>;
			pinctrl-names = "mdss_default", "mdss_sleep";
			pinctrl-0 = <&mdss_dsi_active>, <&mdss_te_active>;
			pinctrl-1 = <&mdss_dsi_suspend>, <&mdss_te_suspend>;
			qcom,pluggable;
			qcom,platform-te-gpio = <&tlmm>, <0x18 0x00>;
			qcom,platform-reset-gpio = <&tlmm>, <0x3d 0x00>;
			qcom,platform-bklight-en-gpio = <&tlmm>, <0x3b 0x00>;
		};
	};

	fragment@27 {
		target = <&soc>;

		__overlay__ {

			gpio_keys {
				compatible = "gpio-keys";
				input-name = "gpio-keys";
				pinctrl-names = "default";
				pinctrl-0 = <&gpio_key_active>;

				camera_focus {
					label = "camera_focus";
					gpios = <&tlmm>, <0x57 0x01>;
					linux,input-type = <0x01>;
					linux,code = <0x210>;
					debounce-interval = <0x0f>;
					linux,can-disable;
					gpio-key,wakeup;
				};

				camera_snapshot {
					label = "camera_snapshot";
					gpios = <&tlmm>, <0x56 0x01>;
					linux,input-type = <0x01>;
					linux,code = <0x2fe>;
					debounce-interval = <0x0f>;
					linux,can-disable;
					gpio-key,wakeup;
				};

				vol_up {
					label = "volume_up";
					gpios = <&tlmm>, <0x55 0x01>;
					linux,input-type = <0x01>;
					linux,code = <0x73>;
					debounce-interval = <0x0f>;
					linux,can-disable;
					gpio-key,wakeup;
				};
			};

			hall {
				compatible = "hall-switch";
				pinctrl-names = "default";
				pinctrl-0 = <&hall_sensor_int_default>;
				interrupt-parent = <&tlmm>;
				interrupts = <0x0d 0x2003>;
				linux,gpio-int = <&tlmm>, <0x0d 0x01>;
				linux,wakeup;
				linux,min-uv = <0x192d50>;
				linux,max-uv = <0x325aa0>;
			};
		};
	};

	fragment@28 {
		target = <&thermal_zones>;

		__overlay__ {

			case-therm-step {
				status = "disabled";
			};

			quiet-therm-step {
				status = "disabled";
			};

			sdm632-skin-step {
				status = "disabled";
			};
		};
	};

	fragment@29 {
		target = <&rpm_bus>;

		__overlay__ {

			rpm-regulator-ldoa6 {

				pm8953_l6: regulator-l6 {
					regulator-always-on;
				};
			};
		};
	};

	fragment@30 {
		target = <&mdss_mdp>;

		__overlay__ {

			dsi_nt36672_csot_fhdp_vid: qcom,mdss_dsi_nt36672_csot_fhdp_video {
				qcom,mdss-dsi-panel-name = "nt36672 csot fhdp video mode dsi panel";
				qcom,mdss-dsi-panel-controller = <&mdss_dsi0>;
				qcom,mdss-dsi-panel-type = "dsi_video_mode";
				qcom,mdss-dsi-panel-destination = "display_1";
				qcom,mdss-dsi-panel-framerate = <0x3c>;
				qcom,mdss-dsi-virtual-channel-id = <0x00>;
				qcom,mdss-dsi-stream = <0x00>;
				qcom,mdss-dsi-panel-width = <0x438>;
				qcom,mdss-dsi-panel-height = <0x870>;
				qcom,mdss-dsi-h-front-porch = <0x28>;
				qcom,mdss-dsi-h-back-porch = <0x27>;
				qcom,mdss-dsi-h-pulse-width = <0x01>;
				qcom,mdss-dsi-h-sync-skew = <0x00>;
				qcom,mdss-dsi-v-back-porch = <0x05>;
				qcom,mdss-dsi-v-front-porch = <0x0e>;
				qcom,mdss-dsi-v-pulse-width = <0x01>;
				qcom,mdss-dsi-h-left-border = <0x00>;
				qcom,mdss-dsi-h-right-border = <0x00>;
				qcom,mdss-dsi-v-top-border = <0x00>;
				qcom,mdss-dsi-v-bottom-border = <0x00>;
				qcom,mdss-dsi-bpp = <0x18>;
				qcom,mdss-dsi-color-order = "rgb_swap_rgb";
				qcom,mdss-dsi-underflow-color = <0xff>;
				qcom,mdss-dsi-border-color = <0x00>;
				qcom,mdss-dsi-on-command = [15 01 00 00 00 00 02 ff 20 15 01 00 00 00 00 02 fb 01 15 01 00 00 00 00 02 06 9e 15 01 00 00 00 00 02 07 94 15 01 00 00 00 00 02 0e 35 15 01 00 00 00 00 02 0f 24 15 01 00 00 00 00 02 68 03 15 01 00 00 00 00 02 6d 66 15 01 00 00 00 00 02 69 99 15 01 00 00 00 00 02 95 eb 15 01 00 00 00 00 02 96 eb 15 01 00 00 00 00 02 ff 20 15 01 00 00 00 00 02 fb 01 39 01 00 00 00 00 11 b0 00 00 00 16 00 39 00 55 00 6e 00 85 00 99 00 ac 39 01 00 00 00 00 11 b1 00 bd 00 f7 01 21 01 65 01 93 01 e0 02 18 02 1a 39 01 00 00 00 00 11 b2 02 53 02 94 02 c3 02 f5 03 15 03 4c 03 56 03 64 39 01 00 00 00 00 0d b3 03 74 03 86 03 9c 03 b6 03 ce 03 ff 39 01 00 00 00 00 11 b4 00 00 00 16 00 39 00 55 00 6e 00 85 00 99 00 ac 39 01 00 00 00 00 11 b5 00 bd 00 f7 01 21 01 65 01 93 01 e0 02 18 02 1a 39 01 00 00 00 00 11 b6 02 53 02 94 02 c3 02 f5 03 15 03 4c 03 56 03 64 39 01 00 00 00 00 0d b7 03 74 03 86 03 9c 03 b6 03 ce 03 ff 39 01 00 00 00 00 11 b8 00 00 00 16 00 39 00 55 00 6e 00 85 00 99 00 ac 39 01 00 00 00 00 11 b9 00 bd 00 f7 01 21 01 65 01 93 01 e0 02 18 02 1a 39 01 00 00 00 00 11 ba 02 53 02 94 02 c3 02 f5 03 15 03 4c 03 56 03 64 39 01 00 00 00 00 0d bb 03 74 03 86 03 9c 03 b6 03 ce 03 ff 15 01 00 00 00 00 02 ff 21 15 01 00 00 00 00 02 fb 01 39 01 00 00 00 00 11 b0 00 00 00 16 00 39 00 55 00 6e 00 85 00 99 00 ac 39 01 00 00 00 00 11 b1 00 bd 00 f7 01 21 01 65 01 93 01 e0 02 18 02 1a 39 01 00 00 00 00 11 b2 02 53 02 94 02 c3 02 f5 03 15 03 4c 03 56 03 64 39 01 00 00 00 00 0d b3 03 74 03 86 03 9c 03 b6 03 ce 03 ff 39 01 00 00 00 00 11 b4 00 00 00 16 00 39 00 55 00 6e 00 85 00 99 00 ac 39 01 00 00 00 00 11 b5 00 bd 00 f7 01 21 01 65 01 93 01 e0 02 18 02 1a 39 01 00 00 00 00 11 b6 02 53 02 94 02 c3 02 f5 03 15 03 4c 03 56 03 64 39 01 00 00 00 00 0d b7 03 74 03 86 03 9c 03 b6 03 ce 03 ff 39 01 00 00 00 00 11 b8 00 00 00 16 00 39 00 55 00 6e 00 85 00 99 00 ac 39 01 00 00 00 00 11 b9 00 bd 00 f7 01 21 01 65 01 93 01 e0 02 18 02 1a 39 01 00 00 00 00 11 ba 02 53 02 94 02 c3 02 f5 03 15 03 4c 03 56 03 64 39 01 00 00 00 00 0d bb 03 74 03 86 03 9c 03 b6 03 ce 03 ff 15 01 00 00 00 00 02 ff 24 15 01 00 00 00 00 02 fb 01 15 01 00 00 00 00 02 00 20 15 01 00 00 00 00 02 01 20 15 01 00 00 00 00 02 02 20 15 01 00 00 00 00 02 03 01 15 01 00 00 00 00 02 04 0b 15 01 00 00 00 00 02 05 0c 15 01 00 00 00 00 02 06 a9 15 01 00 00 00 00 02 07 06 15 01 00 00 00 00 02 08 04 15 01 00 00 00 00 02 09 20 15 01 00 00 00 00 02 0a 0f 15 01 00 00 00 00 02 0b 20 15 01 00 00 00 00 02 0c 20 15 01 00 00 00 00 02 0d 20 15 01 00 00 00 00 02 0e 20 15 01 00 00 00 00 02 0f 17 15 01 00 00 00 00 02 10 15 15 01 00 00 00 00 02 11 13 15 01 00 00 00 00 02 12 00 15 01 00 00 00 00 02 13 00 15 01 00 00 00 00 02 14 20 15 01 00 00 00 00 02 15 01 15 01 00 00 00 00 02 16 0b 15 01 00 00 00 00 02 17 0c 15 01 00 00 00 00 02 18 a9 15 01 00 00 00 00 02 19 05 15 01 00 00 00 00 02 1a 03 15 01 00 00 00 00 02 1b 20 15 01 00 00 00 00 02 1c 0f 15 01 00 00 00 00 02 1d 20 15 01 00 00 00 00 02 1e 20 15 01 00 00 00 00 02 1f 20 15 01 00 00 00 00 02 20 20 15 01 00 00 00 00 02 21 17 15 01 00 00 00 00 02 22 15 15 01 00 00 00 00 02 23 13 15 01 00 00 00 00 02 2f 04 15 01 00 00 00 00 02 30 08 15 01 00 00 00 00 02 31 04 15 01 00 00 00 00 02 32 08 15 01 00 00 00 00 02 33 02 15 01 00 00 00 00 02 34 02 15 01 00 00 00 00 02 35 00 15 01 00 00 00 00 02 37 02 15 01 00 00 00 00 02 38 72 15 01 00 00 00 00 02 39 72 15 01 00 00 00 00 02 3b 40 15 01 00 00 00 00 02 3f 72 15 01 00 00 00 00 02 60 10 15 01 00 00 00 00 02 61 00 15 01 00 00 00 00 02 68 83 15 01 00 00 00 00 02 78 00 15 01 00 00 00 00 02 79 00 15 01 00 00 00 00 02 7a 08 15 01 00 00 00 00 02 7b 9c 15 01 00 00 00 00 02 7d 06 15 01 00 00 00 00 02 7e 02 15 01 00 00 00 00 02 80 45 15 01 00 00 00 00 02 81 06 15 01 00 00 00 00 02 8e f0 15 01 00 00 00 00 02 90 00 15 01 00 00 00 00 02 92 76 15 01 00 00 00 00 02 93 0a 15 01 00 00 00 00 02 94 0a 15 01 00 00 00 00 02 99 33 15 01 00 00 00 00 02 9b ff 15 01 00 00 00 00 02 b3 00 15 01 00 00 00 00 02 b4 04 15 01 00 00 00 00 02 b5 04 15 01 00 00 00 00 02 dc 00 15 01 00 00 00 00 02 dd 01 15 01 00 00 00 00 02 de 00 15 01 00 00 00 00 02 df 00 15 01 00 00 00 00 02 e0 75 15 01 00 00 00 00 02 e9 08 15 01 00 00 00 00 02 ed 40 15 01 00 00 00 00 02 ff 25 15 01 00 00 00 00 02 fb 01 15 01 00 00 00 00 02 0a 81 15 01 00 00 00 00 02 0b d7 15 01 00 00 00 00 02 0c 01 15 01 00 00 00 00 02 17 82 15 01 00 00 00 00 02 21 1c 15 01 00 00 00 00 02 22 1c 15 01 00 00 00 00 02 24 76 15 01 00 00 00 00 02 25 76 15 01 00 00 00 00 02 5c 25 15 01 00 00 00 00 02 5d 80 15 01 00 00 00 00 02 5e 80 15 01 00 00 00 00 02 5f 22 15 01 00 00 00 00 02 65 00 15 01 00 00 00 00 02 69 60 15 01 00 00 00 00 02 6b 00 15 01 00 00 00 00 02 71 2d 15 01 00 00 00 00 02 80 00 15 01 00 00 00 00 02 84 68 15 01 00 00 00 00 02 8d 04 15 01 00 00 00 00 02 d7 00 15 01 00 00 00 00 02 d8 00 15 01 00 00 00 00 02 d9 00 15 01 00 00 00 00 02 da 00 15 01 00 00 00 00 02 db 00 15 01 00 00 00 00 02 dc 00 15 01 00 00 00 00 02 ff 26 15 01 00 00 00 00 02 fb 01 15 01 00 00 00 00 02 06 c8 15 01 00 00 00 00 02 12 5a 15 01 00 00 00 00 02 19 0a 15 01 00 00 00 00 02 1a 97 15 01 00 00 00 00 02 1d 0a 15 01 00 00 00 00 02 1e 1e 15 01 00 00 00 00 02 99 20 15 01 00 00 00 00 02 ff 27 15 01 00 00 00 00 02 fb 01 15 01 00 00 00 00 02 13 0e 15 01 00 00 00 00 02 16 b0 15 01 00 00 00 00 02 17 d0 15 01 00 00 00 00 02 ff 10 15 01 00 00 00 00 02 fb 01 15 01 00 00 00 00 02 51 ff 15 01 00 00 00 00 02 53 24 15 01 00 00 00 00 02 55 00 05 01 00 00 78 00 02 11 00 15 01 00 00 00 00 02 35 00 05 01 00 00 28 00 02 29 00];
				qcom,mdss-dsi-off-command = [15 01 00 00 00 00 02 ff 10 15 01 00 00 00 00 02 fb 01 05 01 00 00 14 00 02 28 00 05 01 00 00 3c 00 02 10 00 15 01 00 00 00 00 02 4f 01];
				qcom,mdss-dsi-on-command-state = "dsi_lp_mode";
				qcom,mdss-dsi-off-command-state = "dsi_lp_mode";
				qcom,mdss-dsi-h-sync-pulse = <0x01>;
				qcom,mdss-dsi-traffic-mode = "burst_mode";
				qcom,mdss-dsi-lane-map = "lane_map_0123";
				qcom,mdss-dsi-bllp-eof-power-mode;
				qcom,mdss-dsi-bllp-power-mode;
				qcom,mdss-dsi-lane-0-state;
				qcom,mdss-dsi-lane-1-state;
				qcom,mdss-dsi-lane-2-state;
				qcom,mdss-dsi-lane-3-state;
				qcom,mdss-dsi-panel-timings = <0xfb382600 0x6a6c2c3c 0x2f030400>;
				qcom,mdss-dsi-panel-timings-phy-v2 = <0x241f0809 0x50304a0 0x241f0809 0x50304a0 0x241f0809 0x50304a0 0x241f0809 0x50304a0 0x241b0809 0x50304a0>;
				qcom,mdss-dsi-t-clk-post = <0x0d>;
				qcom,mdss-dsi-t-clk-pre = <0x30>;
				qcom,mdss-dsi-bl-min-level = <0x01>;
				qcom,mdss-dsi-bl-max-level = <0xff>;
				qcom,esd-check-enabled;
				qcom,mdss-dsi-panel-status-command = <0x6010001 0x10a>;
				qcom,mdss-dsi-panel-status-command-state = "dsi_lp_mode";
				qcom,mdss-dsi-panel-status-read-length = <0x01>;
				qcom,mdss-dsi-panel-status-value = <0x9c>;
				qcom,mdss-dsi-panel-status-check-mode = "reg_read";
				qcom,mdss-dsi-lp11-init;
				qcom,mdss-dsi-tx-eot-append;
				qcom,mdss-pan-physical-width-dimension = <0x44>;
				qcom,mdss-pan-physical-height-dimension = <0x88>;
				qcom,mdss-dsi-dma-trigger = "trigger_sw";
				qcom,mdss-dsi-mdp-trigger = "none";
				qcom,mdss-dsi-bl-pmic-control-type = "bl_ctrl_pwm";
				qcom,mdss-dsi-bl-pmic-pwm-frequency = <0x1f4>;
				qcom,mdss-dsi-bl-pmic-bank-select = <0x00>;
				qcom,mdss-dsi-pwm-gpio = <&pm8953_gpios>, <0x08 0x00>;
				qcom,mdss-dsi-reset-sequence = <0x01 0x05 0x00 0x05 0x01 0x0a>;
				qcom,panel-supply-entries = <&dsi_panel_pwr_supply>;
			};
		};
	};

	fragment@31 {
		target = <&mdss_mdp>;

		__overlay__ {

			dsi_td4310_csot_fhdp_vid: qcom,mdss_dsi_td4310_csot_fhdp_video {
				qcom,mdss-dsi-panel-name = "td4310 csot fhdp video mode dsi panel";
				qcom,mdss-dsi-panel-controller = <&mdss_dsi0>;
				qcom,mdss-dsi-panel-type = "dsi_video_mode";
				qcom,mdss-dsi-panel-destination = "display_1";
				qcom,mdss-dsi-panel-framerate = <0x3c>;
				qcom,mdss-dsi-virtual-channel-id = <0x00>;
				qcom,mdss-dsi-stream = <0x00>;
				qcom,mdss-dsi-panel-width = <0x438>;
				qcom,mdss-dsi-panel-height = <0x870>;
				qcom,mdss-dsi-h-front-porch = <0x38>;
				qcom,mdss-dsi-h-back-porch = <0x10>;
				qcom,mdss-dsi-h-pulse-width = <0x04>;
				qcom,mdss-dsi-h-sync-skew = <0x00>;
				qcom,mdss-dsi-v-back-porch = <0x21>;
				qcom,mdss-dsi-v-front-porch = <0x04>;
				qcom,mdss-dsi-v-pulse-width = <0x02>;
				qcom,mdss-dsi-h-left-border = <0x00>;
				qcom,mdss-dsi-h-right-border = <0x00>;
				qcom,mdss-dsi-v-top-border = <0x00>;
				qcom,mdss-dsi-v-bottom-border = <0x00>;
				qcom,mdss-dsi-bpp = <0x18>;
				qcom,mdss-dsi-color-order = "rgb_swap_rgb";
				qcom,mdss-dsi-underflow-color = <0xff>;
				qcom,mdss-dsi-border-color = <0x00>;
				qcom,mdss-dsi-on-command = [05 01 00 00 64 00 02 11 00 05 01 00 00 14 00 02 29 00];
				qcom,mdss-dsi-off-command = [05 01 00 00 14 00 02 28 00 05 01 00 00 3c 00 02 10 00];
				qcom,mdss-dsi-on-command-state = "dsi_lp_mode";
				qcom,mdss-dsi-off-command-state = "dsi_lp_mode";
				qcom,mdss-dsi-h-sync-pulse = <0x01>;
				qcom,mdss-dsi-traffic-mode = "burst_mode";
				qcom,mdss-dsi-lane-map = "lane_map_0123";
				qcom,mdss-dsi-bllp-eof-power-mode;
				qcom,mdss-dsi-bllp-power-mode;
				qcom,mdss-dsi-lane-0-state;
				qcom,mdss-dsi-lane-1-state;
				qcom,mdss-dsi-lane-2-state;
				qcom,mdss-dsi-lane-3-state;
				qcom,mdss-dsi-panel-timings = <0xf3382600 0x6a6e2c3c 0x2f030400>;
				qcom,mdss-dsi-panel-timings-phy-v2 = <0x241f0809 0x50304a0 0x241f0809 0x50304a0 0x241f0809 0x50304a0 0x241f0809 0x50304a0 0x241b0809 0x50304a0>;
				qcom,mdss-dsi-t-clk-post = <0x0d>;
				qcom,mdss-dsi-t-clk-pre = <0x30>;
				qcom,mdss-dsi-bl-min-level = <0x02>;
				qcom,mdss-dsi-bl-max-level = <0x1ff>;
				qcom,mdss-brightness-max-level = <0x1ff>;
				qcom,esd-check-enabled;
				qcom,mdss-dsi-panel-status-command = <0x6010001 0x10a>;
				qcom,mdss-dsi-panel-status-command-state = "dsi_lp_mode";
				qcom,mdss-dsi-panel-status-read-length = <0x01>;
				qcom,mdss-dsi-panel-status-value = <0x1c>;
				qcom,mdss-dsi-panel-status-check-mode = "reg_read";
				qcom,mdss-dsi-lp11-init;
				qcom,suspend-ulps-enabled;
				qcom,mdss-dsi-tx-eot-append;
				qcom,mdss-pan-physical-width-dimension = <0x44>;
				qcom,mdss-pan-physical-height-dimension = <0x88>;
				qcom,mdss-dsi-dma-trigger = "trigger_sw";
				qcom,mdss-dsi-mdp-trigger = "none";
				qcom,mdss-dsi-bl-pmic-control-type = "bl_ctrl_pwm";
				qcom,mdss-dsi-bl-pmic-pwm-frequency = <0x1f4>;
				qcom,mdss-dsi-bl-pmic-bank-select = <0x00>;
				qcom,mdss-dsi-pwm-gpio = <&pm8953_gpios>, <0x08 0x00>;
				qcom,mdss-dsi-reset-sequence = <0x01 0x05 0x00 0x05 0x01 0x0a>;
				qcom,panel-supply-entries = <&dsi_panel_pwr_supply>;
			};
		};
	};

	fragment@32 {
		target = <&mdss_mdp>;

		__overlay__ {

			dsi_ssd2092_txd_fhdp_vid: qcom,mdss_dsi_ssd2092_txd_fhdp_video {
				qcom,mdss-dsi-panel-name = "ssd2092 txd fhdp video mode dsi panel";
				qcom,mdss-dsi-panel-controller = <&mdss_dsi0>;
				qcom,mdss-dsi-panel-type = "dsi_video_mode";
				qcom,mdss-dsi-panel-destination = "display_1";
				qcom,mdss-dsi-panel-framerate = <0x3c>;
				qcom,mdss-dsi-virtual-channel-id = <0x00>;
				qcom,mdss-dsi-stream = <0x00>;
				qcom,mdss-dsi-panel-width = <0x438>;
				qcom,mdss-dsi-panel-height = <0x870>;
				qcom,mdss-dsi-h-front-porch = <0x14>;
				qcom,mdss-dsi-h-back-porch = <0x14>;
				qcom,mdss-dsi-h-pulse-width = <0x04>;
				qcom,mdss-dsi-h-sync-skew = <0x00>;
				qcom,mdss-dsi-v-back-porch = <0x2b>;
				qcom,mdss-dsi-v-front-porch = <0x4c>;
				qcom,mdss-dsi-v-pulse-width = <0x01>;
				qcom,mdss-dsi-h-left-border = <0x00>;
				qcom,mdss-dsi-h-right-border = <0x00>;
				qcom,mdss-dsi-v-top-border = <0x00>;
				qcom,mdss-dsi-v-bottom-border = <0x00>;
				qcom,mdss-dsi-bpp = <0x18>;
				qcom,mdss-dsi-color-order = "rgb_swap_rgb";
				qcom,mdss-dsi-underflow-color = <0xff>;
				qcom,mdss-dsi-border-color = <0x00>;
				qcom,mdss-dsi-on-command = [29 01 00 00 00 00 03 b5 00 00 29 01 00 00 00 00 03 b3 03 96 29 01 00 00 00 00 03 b4 21 ff 29 01 00 00 00 00 03 e1 00 00 29 01 00 00 00 00 04 e1 03 00 10 29 01 00 00 00 00 03 b0 04 01 29 01 00 00 00 00 03 b0 07 14 29 01 00 00 00 00 03 c6 04 2d 29 01 00 00 00 00 03 b9 0e 44 29 01 00 00 00 00 03 c1 0c 26 29 01 00 00 00 00 03 c1 08 99 29 01 00 00 00 00 03 b9 23 00 29 01 00 00 00 00 03 c2 04 0f 29 01 00 00 00 00 03 b3 19 0b 29 01 00 00 00 00 03 b0 3d c8 29 01 00 00 00 00 03 b3 0f 20 29 01 00 00 00 00 02 36 02 29 01 00 00 00 00 03 c7 01 09 29 01 00 00 00 00 03 b3 15 80 29 01 00 00 00 00 03 b3 1e 02 29 01 00 00 00 00 03 b3 14 c0 29 01 00 00 00 00 03 b3 16 50 29 01 00 00 00 00 03 b3 1c e4 29 01 00 00 00 00 03 b3 28 00 29 01 00 00 00 00 03 b3 24 1f 29 01 00 00 00 00 03 b0 12 00 29 01 00 00 00 00 03 b0 13 16 29 01 00 00 00 00 03 b0 1a 00 29 01 00 00 00 00 03 b0 1b 16 29 01 00 00 00 00 03 c1 0d a5 29 01 00 00 00 00 03 c1 0e a0 29 01 00 00 00 00 17 c3 00 10 21 2e 37 4a 58 69 75 8c 9e a7 a7 ae b3 bd cc cf 58 57 68 7f 29 01 00 00 00 00 17 c3 15 10 21 2e 37 4a 58 69 75 8c 9e a7 a7 ae b3 bd cc cf 58 57 68 7f 29 01 00 00 00 00 03 bb 01 44 29 01 00 00 00 00 03 bb 02 48 29 01 00 00 00 00 03 bb 03 23 29 01 00 00 00 00 03 bb 04 51 29 01 00 00 00 00 03 bb 05 04 29 01 00 00 00 00 03 bb 06 44 29 01 00 00 00 00 03 bb 07 44 29 01 00 00 00 00 03 bb 08 4e 29 01 00 00 00 00 03 bb 09 dc 29 01 00 00 00 00 03 bb 0a 0c 29 01 00 00 00 00 03 bb 0b 20 29 01 00 00 00 00 03 bb 0c 00 29 01 00 00 00 00 03 bb 0d 33 29 01 00 00 00 00 03 bb 0e 48 29 01 00 00 00 00 03 bb 0f 23 29 01 00 00 00 00 03 bb 10 51 29 01 00 00 00 00 03 bb 11 04 29 01 00 00 00 00 03 bb 12 44 29 01 00 00 00 00 03 bb 13 44 29 01 00 00 00 00 03 bb 14 4e 29 01 00 00 00 00 03 bb 15 dc 29 01 00 00 00 00 03 bb 16 cc 29 01 00 00 00 00 03 bb 17 20 29 01 00 00 00 00 03 bb 18 00 29 01 00 00 00 00 03 bd 2e 00 29 01 00 00 00 00 03 bd 2f 00 29 01 00 00 00 00 03 bd 31 22 29 01 00 00 00 00 03 bd 34 00 29 01 00 00 00 00 03 bd 35 00 29 01 00 00 00 00 03 bd 37 22 29 01 00 00 00 00 03 bd 04 04 29 01 00 00 00 00 03 bd 06 04 29 01 00 00 00 00 03 bd 1a 35 29 01 00 00 00 00 03 bd 1b 53 29 01 00 00 00 00 03 bd 1c 01 29 01 00 00 00 00 03 bd 1d 02 29 01 00 00 00 00 03 bd 1e 02 29 01 00 00 00 00 03 bd 21 00 29 01 00 00 00 00 03 bd 23 24 29 01 00 00 00 00 03 bd 24 42 29 01 00 00 00 00 03 bd 25 01 29 01 00 00 00 00 03 bd 26 02 29 01 00 00 00 00 03 bd 27 02 29 01 00 00 00 00 03 bd 2a 00 29 01 00 00 00 00 03 bd 3a 1d 29 01 00 00 00 00 03 bd 3b 1d 29 01 00 00 00 00 03 bd 3c 1d 29 01 00 00 00 00 03 bd 3d 1d 29 01 00 00 00 00 03 bd 40 aa 29 01 00 00 00 00 03 bd 3f 00 29 01 00 00 00 00 03 bd 41 00 29 01 00 00 00 00 03 bd 42 1d 29 01 00 00 00 00 03 bd 43 1d 29 01 00 00 00 00 03 bd 44 1d 29 01 00 00 00 00 03 bd 45 1d 29 01 00 00 00 00 03 bd 48 aa 29 01 00 00 00 00 03 bd 47 00 29 01 00 00 00 00 03 bd 49 00 29 01 00 00 00 00 03 ba 03 02 29 01 00 00 00 00 03 bc 1e 74 29 01 00 00 00 00 03 bc 24 83 29 01 00 00 00 00 03 bd 2c 33 29 01 00 00 00 00 03 bd 2d 33 29 01 00 00 00 00 03 bd 00 f4 29 01 00 00 00 00 03 bd 01 f0 29 01 00 00 00 00 03 bd 02 f4 29 01 00 00 00 00 03 bd 03 f0 29 01 00 00 00 00 03 bd 0a 00 29 01 00 00 00 00 03 bd 0e 3e 29 01 00 00 00 00 03 bb 19 44 29 01 00 00 00 00 03 bb 1a 49 29 01 00 00 00 00 03 bb 1b 32 29 01 00 00 00 00 03 bb 1c 53 29 01 00 00 00 00 03 bb 1d 24 29 01 00 00 00 00 03 bb 1e 44 29 01 00 00 00 00 03 bb 1f 44 29 01 00 00 00 00 03 bb 20 4e 29 01 00 00 00 00 03 bb 21 dc 29 01 00 00 00 00 03 bb 22 0c 29 01 00 00 00 00 03 bb 23 20 29 01 00 00 00 00 03 bb 24 00 29 01 00 00 00 00 03 bb 25 33 29 01 00 00 00 00 03 bb 26 49 29 01 00 00 00 00 03 bb 27 32 29 01 00 00 00 00 03 bb 28 53 29 01 00 00 00 00 03 bb 29 24 29 01 00 00 00 00 03 bb 2a 44 29 01 00 00 00 00 03 bb 2b 44 29 01 00 00 00 00 03 bb 2c 4e 29 01 00 00 00 00 03 bb 2d dc 29 01 00 00 00 00 03 bb 2e 0c 29 01 00 00 00 00 03 bb 2f 20 29 01 00 00 00 00 03 bb 30 00 29 01 00 00 00 00 04 c6 00 03 40 29 01 00 00 00 00 03 b3 18 00 29 01 00 00 00 00 03 ba 17 28 29 01 00 00 00 00 03 ba 23 15 29 01 00 00 00 00 03 b0 06 2c 29 01 00 00 00 00 03 ba 17 28 29 01 00 00 00 00 03 ba 23 15 29 01 00 00 00 00 03 ba 16 00 29 01 00 00 00 00 04 ba 28 02 02 29 01 00 00 00 00 03 ba 0f 8c 29 01 00 00 00 00 03 ba 10 0c 29 01 00 00 00 00 03 ba 11 1e 29 01 00 00 00 00 05 ba 12 9d 9d 9d 29 01 00 00 00 00 03 ba 25 1c 29 01 00 00 00 00 04 ba 0d 40 02 29 01 00 00 00 00 03 ba 2f 8c 29 01 00 00 00 00 03 c2 04 01 29 01 00 00 00 00 0b b9 11 00 00 00 00 00 00 00 00 00 29 01 00 00 00 00 03 ba 15 33 29 01 00 00 00 00 03 bd 08 02 29 01 00 00 00 00 03 bd 0c 04 29 01 00 00 00 00 03 bd 09 00 29 01 00 00 00 00 03 bd 0d 2f 29 01 00 00 00 00 03 bc 03 03 29 01 00 00 00 00 03 bc 04 00 29 01 00 00 00 00 03 bc 05 00 29 01 00 00 00 00 03 bc 07 10 29 01 00 00 00 00 03 bc 08 11 29 01 00 00 00 00 03 bc 09 14 29 01 00 00 00 00 03 b9 11 53 29 01 00 00 00 00 03 b9 12 35 29 01 00 00 00 00 03 b9 13 33 29 01 00 00 00 00 03 b9 1d 99 29 01 00 00 00 00 03 b9 1e 99 29 01 00 00 00 00 03 b9 1f 99 29 01 00 00 00 00 03 b8 15 a2 29 01 00 00 00 00 03 b8 1b f2 29 01 00 00 00 00 03 b8 16 af 29 01 00 00 00 00 03 b8 1c af 29 01 00 00 00 00 03 b8 17 fa 29 01 00 00 00 00 03 e1 07 12 29 01 00 00 00 00 03 e1 08 10 29 01 00 00 00 00 03 b8 0e 00 29 01 00 00 00 00 03 b8 11 00 29 01 00 00 00 00 03 ec 01 45 29 01 00 00 00 00 03 ec 02 00 29 01 00 00 00 00 03 ec 02 04 29 01 00 00 00 00 03 b1 05 2f 29 01 00 00 00 00 02 35 00 29 01 00 00 00 00 04 b0 01 08 70 29 01 00 00 00 00 03 c2 00 07 29 01 00 00 00 00 06 b9 00 62 62 62 0a 29 01 00 00 00 00 03 b9 0b 02 29 01 00 00 00 00 03 b9 0d 44 29 01 00 00 00 00 03 b9 0e 44 29 01 00 00 00 00 03 c1 02 b0 29 01 00 00 00 00 03 b3 1c c4 29 01 00 00 00 00 03 b3 1d 80 29 01 00 00 00 00 04 bd 11 02 22 05 01 00 00 00 00 02 11 00 05 01 00 00 32 00 02 29 00];
				qcom,mdss-dsi-off-command = [05 01 00 00 14 00 02 28 00 05 01 00 00 78 00 02 10 00];
				qcom,mdss-dsi-on-command-state = "dsi_lp_mode";
				qcom,mdss-dsi-off-command-state = "dsi_hs_mode";
				qcom,mdss-dsi-h-sync-pulse = <0x01>;
				qcom,mdss-dsi-traffic-mode = "burst_mode";
				qcom,mdss-dsi-lane-map = "lane_map_0123";
				qcom,mdss-dsi-bllp-eof-power-mode;
				qcom,mdss-dsi-bllp-power-mode;
				qcom,mdss-dsi-lane-0-state;
				qcom,mdss-dsi-lane-1-state;
				qcom,mdss-dsi-lane-2-state;
				qcom,mdss-dsi-lane-3-state;
				qcom,mdss-dsi-panel-timings = <0xf23a2800 0x6c6e2c3e 0x2e030400>;
				qcom,mdss-dsi-panel-timings-phy-v2 = <0x241f0809 0x50304a0 0x241f0809 0x50304a0 0x241f0809 0x50304a0 0x241f0809 0x50304a0 0x241c0809 0x50304a0>;
				qcom,mdss-dsi-t-clk-post = <0x02>;
				qcom,mdss-dsi-t-clk-pre = <0x2d>;
				qcom,mdss-dsi-bl-min-level = <0x01>;
				qcom,mdss-dsi-bl-max-level = <0x1ff>;
				qcom,mdss-brightness-max-level = <0x1ff>;
				qcom,mdss-dsi-lp11-init;
				qcom,mdss-dsi-tx-eot-append;
				qcom,mdss-pan-physical-width-dimension = <0x44>;
				qcom,mdss-pan-physical-height-dimension = <0x88>;
				qcom,mdss-dsi-dma-trigger = "trigger_sw";
				qcom,mdss-dsi-mdp-trigger = "none";
				qcom,mdss-dsi-bl-pmic-control-type = "bl_ctrl_pwm";
				qcom,mdss-dsi-bl-pmic-pwm-frequency = <0x1f4>;
				qcom,mdss-dsi-bl-pmic-bank-select = <0x00>;
				qcom,mdss-dsi-pwm-gpio = <&pm8953_gpios>, <0x08 0x00>;
				qcom,mdss-dsi-reset-sequence = <0x01 0x05 0x00 0x14 0x01 0x78>;
				qcom,panel-supply-entries = <&dsi_panel_pwr_supply>;
			};
		};
	};

	fragment@33 {
		target = <&mdss_dsi0>;

		__overlay__ {
			qcom,dsi-pref-prim-pan = <&dsi_sim_vid>;
			qcom,dsi-pref-sub-pan = <&dsi_nt36672_csot_fhdp_vid>;
			qcom,dsi-pref-sub1-pan = <&dsi_td4310_csot_fhdp_vid>;
			qcom,dsi-pref-sub2-pan = <&dsi_ssd2092_txd_fhdp_vid>;
			pinctrl-names = "mdss_default", "mdss_sleep";
			pinctrl-0 = <&mdss_dsi_active>;
			pinctrl-1 = <&mdss_dsi_suspend>;
			lab-supply = <&lcdb_ldo_vreg>;
			ibb-supply = <&lcdb_ncp_vreg>;
		};
	};
};
